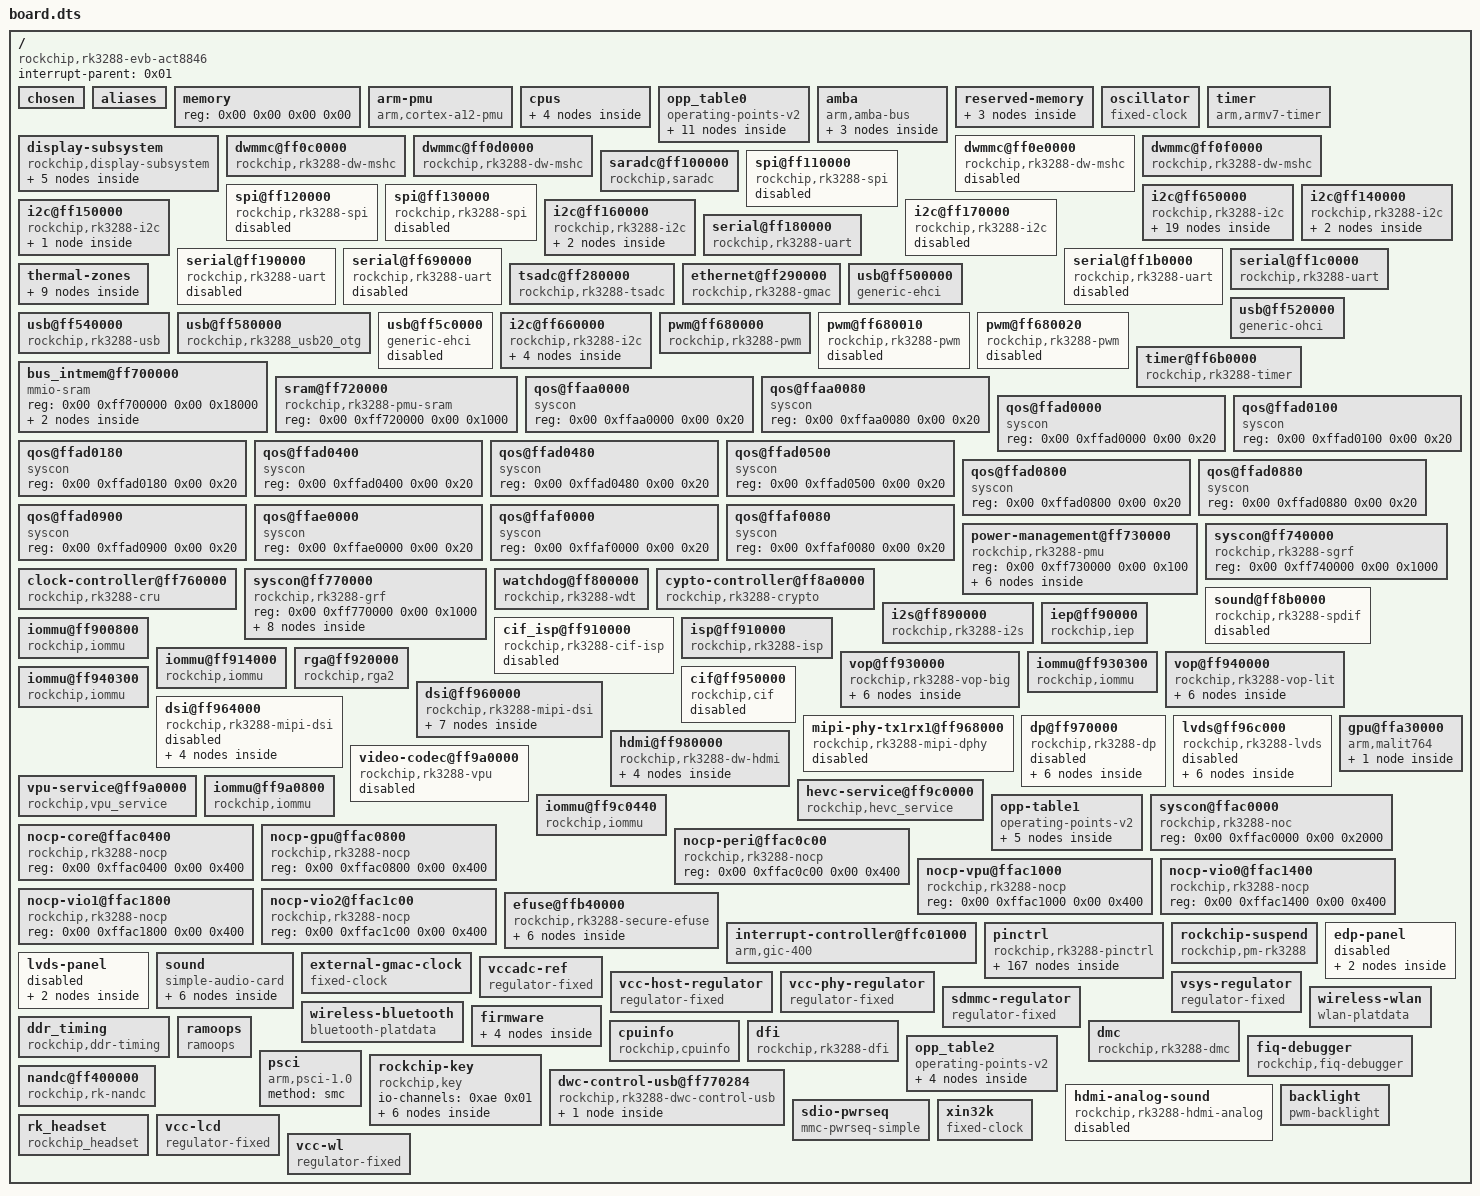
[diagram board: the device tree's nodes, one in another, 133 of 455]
/dts-v1/;

/ {
	#address-cells = <0x02>;
	#size-cells = <0x02>;
	compatible = "rockchip,rk3288-evb-act8846", "rockchip,rk3288";
	interrupt-parent = <0x01>;

	chosen {
		bootargs = "earlycon=uart8250,mmio32,0xff690000 vmalloc=496M";
	};

	aliases {
		ethernet0 = "/ethernet@ff290000";
		i2c0 = "/i2c@ff650000";
		i2c1 = "/i2c@ff140000";
		i2c2 = "/i2c@ff660000";
		i2c3 = "/i2c@ff150000";
		i2c4 = "/i2c@ff160000";
		i2c5 = "/i2c@ff170000";
		mshc0 = "/dwmmc@ff0f0000";
		mshc1 = "/dwmmc@ff0c0000";
		mshc2 = "/dwmmc@ff0d0000";
		mshc3 = "/dwmmc@ff0e0000";
		serial0 = "/serial@ff180000";
		serial1 = "/serial@ff190000";
		serial2 = "/serial@ff690000";
		serial3 = "/serial@ff1b0000";
		serial4 = "/serial@ff1c0000";
		spi0 = "/spi@ff110000";
		spi1 = "/spi@ff120000";
		spi2 = "/spi@ff130000";
		dsi0 = "/dsi@ff960000";
		dsi1 = "/dsi@ff964000";
	};

	memory {
		device_type = "memory";
		reg = <0x00 0x00 0x00 0x00>;
	};

	arm-pmu {
		compatible = "arm,cortex-a12-pmu";
		interrupts = <0x00 0x97 0x04 0x00 0x98 0x04 0x00 0x99 0x04 0x00 0x9a 0x04>;
		interrupt-affinity = <0x02 0x03 0x04 0x05>;
	};

	cpus {
		#address-cells = <0x01>;
		#size-cells = <0x00>;
		enable-method = "rockchip,rk3066-smp";
		rockchip,pmu = <0x06>;

		cpu@500 {
			device_type = "cpu";
			compatible = "arm,cortex-a12";
			reg = <0x500>;
			resets = <0x07 0x00>;
			operating-points-v2 = <0x08>;
			#cooling-cells = <0x02>;
			dynamic-power-coefficient = <0x142>;
			clocks = <0x07 0x06>;
			enable-method = "psci";
			cpu-supply = <0x09>;
			phandle = <0x02>;
		};

		cpu@501 {
			device_type = "cpu";
			compatible = "arm,cortex-a12";
			reg = <0x501>;
			resets = <0x07 0x01>;
			operating-points-v2 = <0x08>;
			enable-method = "psci";
			phandle = <0x03>;
		};

		cpu@502 {
			device_type = "cpu";
			compatible = "arm,cortex-a12";
			reg = <0x502>;
			resets = <0x07 0x02>;
			operating-points-v2 = <0x08>;
			enable-method = "psci";
			phandle = <0x04>;
		};

		cpu@503 {
			device_type = "cpu";
			compatible = "arm,cortex-a12";
			reg = <0x503>;
			resets = <0x07 0x03>;
			operating-points-v2 = <0x08>;
			enable-method = "psci";
			phandle = <0x05>;
		};
	};

	opp_table0 {
		compatible = "operating-points-v2";
		opp-shared;
		clocks = <0x07 0x01>;
		rockchip,avs-scale = <0x11>;
		rockchip,max-volt = <0x149970>;
		nvmem-cells = <0x0a 0x0b 0x0c 0x0d 0x0e>;
		nvmem-cell-names = "leakage", "special", "performance", "process", "performance-w";
		rockchip,bin-scaling-sel = <0x00 0x11 0x01 0x19 0x02 0x1b 0x03 0x1f>;
		rockchip,pvtm-voltage-sel = <0x00 0x37dc 0x00 0x37dd 0x3a98 0x01 0x3a99 0x3e80 0x02 0x3e81 0x1869f 0x03>;
		rockchip,pvtm-freq = <0x639c0>;
		rockchip,pvtm-volt = <0xf4240>;
		rockchip,pvtm-ch = <0x00 0x00>;
		rockchip,pvtm-sample-time = <0x3e8>;
		rockchip,pvtm-number = <0x0a>;
		rockchip,pvtm-error = <0x3e8>;
		rockchip,pvtm-ref-temp = <0x23>;
		rockchip,pvtm-temp-prop = <0xffffffee 0xffffffee>;
		rockchip,pvtm-thermal-zone = "soc-thermal";
		rockchip,avs-enable = <0x01>;
		phandle = <0x08>;

		opp-126000000 {
			opp-hz = <0x00 0x7829b80>;
			opp-microvolt = <0xe7ef0 0xe7ef0 0x149970>;
			opp-microvolt-L0 = <0xe7ef0 0xe7ef0 0x149970>;
			opp-microvolt-L1 = <0xe7ef0 0xe7ef0 0x149970>;
			opp-microvolt-L2 = <0xe7ef0 0xe7ef0 0x149970>;
			opp-microvolt-L3 = <0xe7ef0 0xe7ef0 0x149970>;
			clock-latency-ns = <0x9c40>;
		};

		opp-216000000 {
			opp-hz = <0x00 0xcdfe600>;
			opp-microvolt = <0xe7ef0 0xe7ef0 0x149970>;
			opp-microvolt-L0 = <0xe7ef0 0xe7ef0 0x149970>;
			opp-microvolt-L1 = <0xe7ef0 0xe7ef0 0x149970>;
			opp-microvolt-L2 = <0xe7ef0 0xe7ef0 0x149970>;
			opp-microvolt-L3 = <0xe7ef0 0xe7ef0 0x149970>;
			clock-latency-ns = <0x9c40>;
		};

		opp-408000000 {
			opp-hz = <0x00 0x18519600>;
			opp-microvolt = <0xee098 0xee098 0x149970>;
			opp-microvolt-L0 = <0xee098 0xee098 0x149970>;
			opp-microvolt-L1 = <0xe7ef0 0xe7ef0 0x149970>;
			opp-microvolt-L2 = <0xe7ef0 0xe7ef0 0x149970>;
			opp-microvolt-L3 = <0xe7ef0 0xe7ef0 0x149970>;
			clock-latency-ns = <0x9c40>;
		};

		opp-600000000 {
			opp-hz = <0x00 0x23c34600>;
			opp-microvolt = <0xee098 0xee098 0x149970>;
			opp-microvolt-L0 = <0xee098 0xee098 0x149970>;
			opp-microvolt-L1 = <0xe7ef0 0xe7ef0 0x149970>;
			opp-microvolt-L2 = <0xe7ef0 0xe7ef0 0x149970>;
			opp-microvolt-L3 = <0xe7ef0 0xe7ef0 0x149970>;
			clock-latency-ns = <0x9c40>;
		};

		opp-696000000 {
			opp-hz = <0x00 0x297c1e00>;
			opp-microvolt = <0xee098 0xee098 0x149970>;
			opp-microvolt-L0 = <0xee098 0xee098 0x149970>;
			opp-microvolt-L1 = <0xe7ef0 0xe7ef0 0x149970>;
			opp-microvolt-L2 = <0xe7ef0 0xe7ef0 0x149970>;
			opp-microvolt-L3 = <0xe7ef0 0xe7ef0 0x149970>;
			clock-latency-ns = <0x9c40>;
		};

		opp-816000000 {
			opp-hz = <0x00 0x30a32c00>;
			opp-microvolt = <0x106738 0x106738 0x149970>;
			opp-microvolt-L0 = <0x106738 0x106738 0x149970>;
			opp-microvolt-L1 = <0x100590 0x100590 0x149970>;
			opp-microvolt-L2 = <0xf4240 0xf4240 0x149970>;
			opp-microvolt-L3 = <0xe7ef0 0xe7ef0 0x149970>;
			clock-latency-ns = <0x9c40>;
			opp-suspend;
		};

		opp-1008000000 {
			opp-hz = <0x00 0x3c14dc00>;
			opp-microvolt = <0x118c30 0x118c30 0x149970>;
			opp-microvolt-L0 = <0x118c30 0x118c30 0x149970>;
			opp-microvolt-L1 = <0x10c8e0 0x10c8e0 0x149970>;
			opp-microvolt-L2 = <0x100590 0x100590 0x149970>;
			opp-microvolt-L3 = <0xf4240 0xf4240 0x149970>;
			clock-latency-ns = <0x9c40>;
		};

		opp-1200000000 {
			opp-hz = <0x00 0x47868c00>;
			opp-microvolt = <0x124f80 0x124f80 0x149970>;
			opp-microvolt-L0 = <0x124f80 0x124f80 0x149970>;
			opp-microvolt-L1 = <0x118c30 0x118c30 0x149970>;
			opp-microvolt-L2 = <0x10c8e0 0x10c8e0 0x149970>;
			opp-microvolt-L3 = <0x100590 0x100590 0x149970>;
			clock-latency-ns = <0x9c40>;
		};

		opp-1416000000 {
			opp-hz = <0x00 0x54667200>;
			opp-microvolt = <0x13d620 0x13d620 0x149970>;
			opp-microvolt-L0 = <0x13d620 0x13d620 0x149970>;
			opp-microvolt-L1 = <0x1312d0 0x1312d0 0x149970>;
			opp-microvolt-L2 = <0x124f80 0x124f80 0x149970>;
			opp-microvolt-L3 = <0x118c30 0x118c30 0x149970>;
			clock-latency-ns = <0x9c40>;
		};

		opp-1512000000 {
			opp-hz = <0x00 0x5a1f4a00>;
			opp-microvolt = <0x149970 0x149970 0x149970>;
			opp-microvolt-L0 = <0x149970 0x149970 0x149970>;
			opp-microvolt-L1 = <0x13d620 0x13d620 0x149970>;
			opp-microvolt-L2 = <0x1312d0 0x1312d0 0x149970>;
			opp-microvolt-L3 = <0x124f80 0x124f80 0x149970>;
			clock-latency-ns = <0x9c40>;
		};

		opp-1608000000 {
			opp-hz = <0x00 0x5fd82200>;
			opp-microvolt = <0x149970 0x149970 0x149970>;
			opp-microvolt-L0 = <0x149970 0x149970 0x149970>;
			opp-microvolt-L1 = <0x149970 0x149970 0x149970>;
			opp-microvolt-L2 = <0x13d620 0x13d620 0x149970>;
			opp-microvolt-L3 = <0x1312d0 0x1312d0 0x149970>;
			clock-latency-ns = <0x9c40>;
		};
	};

	amba {
		compatible = "arm,amba-bus";
		#address-cells = <0x02>;
		#size-cells = <0x02>;
		ranges;

		dma-controller@ff250000 {
			compatible = "arm,pl330", "arm,primecell";
			reg = <0x00 0xff250000 0x00 0x4000>;
			interrupts = <0x00 0x02 0x04 0x00 0x03 0x04>;
			#dma-cells = <0x01>;
			arm,pl330-broken-no-flushp;
			peripherals-req-type-burst;
			clocks = <0x07 0xc2>;
			clock-names = "apb_pclk";
			phandle = <0x26>;
		};

		dma-controller@ff600000 {
			compatible = "arm,pl330", "arm,primecell";
			reg = <0x00 0xff600000 0x00 0x4000>;
			interrupts = <0x00 0x00 0x04 0x00 0x01 0x04>;
			#dma-cells = <0x01>;
			arm,pl330-broken-no-flushp;
			peripherals-req-type-burst;
			clocks = <0x07 0xc1>;
			clock-names = "apb_pclk";
			status = "disabled";
		};

		dma-controller@ffb20000 {
			compatible = "arm,pl330", "arm,primecell";
			reg = <0x00 0xff600000 0x00 0x4000>;
			interrupts = <0x00 0x00 0x04 0x00 0x01 0x04>;
			#dma-cells = <0x01>;
			arm,pl330-broken-no-flushp;
			peripherals-req-type-burst;
			clocks = <0x07 0xc1>;
			clock-names = "apb_pclk";
			phandle = <0x69>;
		};
	};

	reserved-memory {
		#address-cells = <0x02>;
		#size-cells = <0x02>;
		ranges;

		dma-unusable@fe000000 {
			reg = <0x00 0xfe000000 0x00 0x1000000>;
		};

		ramoops@00000000 {
			reg = <0x00 0x8000000 0x00 0xf0000>;
			phandle = <0xad>;
		};

		drm-logo@00000000 {
			compatible = "rockchip,drm-logo";
			reg = <0x00 0x00 0x00 0x00>;
			phandle = <0x11>;
		};
	};

	oscillator {
		compatible = "fixed-clock";
		clock-frequency = <0x16e3600>;
		clock-output-names = "xin24m";
		#clock-cells = <0x00>;
		phandle = <0x59>;
	};

	timer {
		compatible = "arm,armv7-timer";
		arm,cpu-registers-not-fw-configured;
		interrupts = <0x01 0x0d 0xf04 0x01 0x0e 0xf04 0x01 0x0b 0xf04 0x01 0x0a 0xf04>;
		clock-frequency = <0x16e3600>;
	};

	display-subsystem {
		compatible = "rockchip,display-subsystem";
		ports = <0x0f 0x10>;
		status = "okay";
		logo-memory-region = <0x11>;

		route {

			route-edp {
				status = "disabled";
				logo,uboot = "logo.bmp";
				logo,kernel = "logo_kernel.bmp";
				logo,mode = "center";
				charge_logo,mode = "center";
				connect = <0x12>;
			};

			route-dsi0 {
				status = "okay";
				logo,uboot = "logo.bmp";
				logo,kernel = "logo_kernel.bmp";
				logo,mode = "center";
				charge_logo,mode = "center";
				connect = <0x13>;
			};

			route-lvds {
				status = "disabled";
				logo,uboot = "logo.bmp";
				logo,kernel = "logo_kernel.bmp";
				logo,mode = "center";
				charge_logo,mode = "center";
				connect = <0x14>;
			};

			route-hdmi {
				status = "disabled";
				logo,uboot = "logo.bmp";
				logo,kernel = "logo_kernel.bmp";
				logo,mode = "center";
				charge_logo,mode = "center";
				connect = <0x15>;
			};
		};
	};

	dwmmc@ff0c0000 {
		compatible = "rockchip,rk3288-dw-mshc";
		clock-freq-min-max = <0x61a80 0x8f0d180>;
		clocks = <0x07 0x1c8 0x07 0x44 0x07 0x72 0x07 0x76>;
		clock-names = "biu", "ciu", "ciu-drive", "ciu-sample";
		fifo-depth = <0x100>;
		interrupts = <0x00 0x20 0x04>;
		reg = <0x00 0xff0c0000 0x00 0x4000>;
		status = "okay";
		supports-sd;
		bus-width = <0x04>;
		cap-mmc-highspeed;
		sd-uhs-sdr12;
		sd-uhs-sdr25;
		sd-uhs-sdr50;
		sd-uhs-sdr104;
		cap-sd-highspeed;
		card-detect-delay = <0xc8>;
		disable-wp;
		num-slots = <0x01>;
		pinctrl-names = "default";
		pinctrl-0 = <0x16 0x17 0x18 0x19>;
		vmmc-supply = <0x1a>;
		vqmmc-supply = <0x1b>;
	};

	dwmmc@ff0d0000 {
		compatible = "rockchip,rk3288-dw-mshc";
		clock-freq-min-max = <0x61a80 0x8f0d180>;
		clocks = <0x07 0x1c9 0x07 0x45 0x07 0x73 0x07 0x77>;
		clock-names = "biu", "ciu", "ciu-drive", "ciu-sample";
		fifo-depth = <0x100>;
		interrupts = <0x00 0x21 0x04>;
		reg = <0x00 0xff0d0000 0x00 0x4000>;
		status = "okay";
		max-frequency = <0x8f0d180>;
		bus-width = <0x04>;
		cap-sd-highspeed;
		disable-wp;
		keep-power-in-suspend;
		mmc-pwrseq = <0x1c>;
		non-removable;
		num-slots = <0x01>;
		pinctrl-names = "default";
		pinctrl-0 = <0x1d 0x1e 0x1f 0x20>;
		sd-uhs-sdr104;
		supports-sdio;
	};

	dwmmc@ff0e0000 {
		compatible = "rockchip,rk3288-dw-mshc";
		clock-freq-min-max = <0x61a80 0x8f0d180>;
		clocks = <0x07 0x1ca 0x07 0x46 0x07 0x74 0x07 0x78>;
		clock-names = "biu", "ciu", "ciu-drive", "ciu-sample";
		fifo-depth = <0x100>;
		interrupts = <0x00 0x22 0x04>;
		reg = <0x00 0xff0e0000 0x00 0x4000>;
		status = "disabled";
	};

	dwmmc@ff0f0000 {
		compatible = "rockchip,rk3288-dw-mshc";
		clock-freq-min-max = <0x61a80 0x8f0d180>;
		clocks = <0x07 0x1cb 0x07 0x47 0x07 0x75 0x07 0x79>;
		clock-names = "biu", "ciu", "ciu-drive", "ciu-sample";
		fifo-depth = <0x100>;
		interrupts = <0x00 0x23 0x04>;
		reg = <0x00 0xff0f0000 0x00 0x4000>;
		status = "okay";
		supports-emmc;
		bus-width = <0x08>;
		cap-mmc-highspeed;
		disable-wp;
		non-removable;
		num-slots = <0x01>;
		pinctrl-names = "default";
		pinctrl-0 = <0x21 0x22 0x23 0x24>;
		max-frequency = <0x5f5e100>;
		mmc-hs200-1_8v;
		mmc-ddr-1_8v;
	};

	saradc@ff100000 {
		compatible = "rockchip,saradc";
		reg = <0x00 0xff100000 0x00 0x100>;
		interrupts = <0x00 0x24 0x04>;
		#io-channel-cells = <0x01>;
		clocks = <0x07 0x49 0x07 0x15b>;
		clock-names = "saradc", "apb_pclk";
		resets = <0x07 0x57>;
		reset-names = "saradc-apb";
		status = "okay";
		vref-supply = <0x25>;
		phandle = <0xae>;
	};

	spi@ff110000 {
		compatible = "rockchip,rk3288-spi", "rockchip,rk3066-spi";
		clocks = <0x07 0x41 0x07 0x152>;
		clock-names = "spiclk", "apb_pclk";
		dmas = <0x26 0x0b 0x26 0x0c>;
		dma-names = "tx", "rx";
		interrupts = <0x00 0x2c 0x04>;
		pinctrl-names = "default";
		pinctrl-0 = <0x27 0x28 0x29 0x2a>;
		reg = <0x00 0xff110000 0x00 0x1000>;
		#address-cells = <0x01>;
		#size-cells = <0x00>;
		status = "disabled";
	};

	spi@ff120000 {
		compatible = "rockchip,rk3288-spi", "rockchip,rk3066-spi";
		clocks = <0x07 0x42 0x07 0x153>;
		clock-names = "spiclk", "apb_pclk";
		dmas = <0x26 0x0d 0x26 0x0e>;
		dma-names = "tx", "rx";
		interrupts = <0x00 0x2d 0x04>;
		pinctrl-names = "default";
		#pinctrl-0 = <0x2b 0x2c 0x2d 0x2e>;
		reg = <0x00 0xff120000 0x00 0x1000>;
		#address-cells = <0x01>;
		#size-cells = <0x00>;
		status = "disabled";
	};

	spi@ff130000 {
		compatible = "rockchip,rk3288-spi", "rockchip,rk3066-spi";
		clocks = <0x07 0x43 0x07 0x154>;
		clock-names = "spiclk", "apb_pclk";
		dmas = <0x26 0x0f 0x26 0x10>;
		dma-names = "tx", "rx";
		interrupts = <0x00 0x2e 0x04>;
		pinctrl-names = "default";
		pinctrl-0 = <0x2f 0x30 0x31 0x32>;
		reg = <0x00 0xff130000 0x00 0x1000>;
		#address-cells = <0x01>;
		#size-cells = <0x00>;
		status = "disabled";
	};

	i2c@ff650000 {
		compatible = "rockchip,rk3288-i2c";
		reg = <0x00 0xff650000 0x00 0x1000>;
		interrupts = <0x00 0x3c 0x04>;
		#address-cells = <0x01>;
		#size-cells = <0x00>;
		clock-names = "i2c";
		clocks = <0x07 0x14c>;
		pinctrl-names = "default";
		pinctrl-0 = <0x33>;
		status = "okay";
		clock-frequency = <0x61a80>;

		syr827@40 {
			compatible = "silergy,syr827";
			fcs,suspend-voltage-selector = <0x01>;
			reg = <0x40>;
			regulator-name = "vdd_cpu";
			regulator-min-microvolt = <0xcf850>;
			regulator-max-microvolt = <0x149970>;
			regulator-always-on;
			regulator-boot-on;
			regulator-enable-ramp-delay = <0x12c>;
			regulator-ramp-delay = <0x1f40>;
			vin-supply = <0x34>;
			phandle = <0x09>;

			regulator-state-mem {
				regulator-off-in-suspend;
			};
		};

		syr828@41 {
			compatible = "silergy,syr828";
			fcs,suspend-voltage-selector = <0x01>;
			reg = <0x41>;
			regulator-name = "vdd_gpu";
			regulator-min-microvolt = <0xcf850>;
			regulator-max-microvolt = <0x149970>;
			regulator-always-on;
			regulator-ramp-delay = <0x1770>;
			vin-supply = <0x34>;
			phandle = <0x95>;

			regulator-state-mem {
				regulator-off-in-suspend;
			};
		};

		hym8563@51 {
			compatible = "rtc,hym8563";
			reg = <0x51>;
			phandle = <0xb3>;
		};

		act8846@5a {
			compatible = "active-semi,act8846";
			reg = <0x5a>;
			status = "okay";
			vp1-supply = <0x34>;
			vp2-supply = <0x34>;
			vp3-supply = <0x34>;
			vp4-supply = <0x34>;
			inl1-supply = <0x35>;
			inl2-supply = <0x34>;
			inl3-supply = <0x36>;

			regulators {

				REG1 {
					regulator-name = "VCC_DDR";
					regulator-min-microvolt = <0x124f80>;
					regulator-max-microvolt = <0x124f80>;
					regulator-always-on;
				};

				REG2 {
					regulator-name = "VCC_IO";
					regulator-min-microvolt = <0x325aa0>;
					regulator-max-microvolt = <0x325aa0>;
					regulator-always-on;
					phandle = <0x35>;
				};

				REG3 {
					regulator-name = "VDD_LOG";
					regulator-min-microvolt = <0x118c30>;
					regulator-max-microvolt = <0x118c30>;
					regulator-always-on;
					phandle = <0xac>;
				};

				REG4 {
					regulator-name = "VCC_20";
					regulator-min-microvolt = <0x1e8480>;
					regulator-max-microvolt = <0x1e8480>;
					regulator-always-on;
					phandle = <0x36>;
				};

				REG5 {
					regulator-name = "VCCIO_SD";
					regulator-min-microvolt = <0x1b7740>;
					regulator-max-microvolt = <0x325aa0>;
					regulator-always-on;
					phandle = <0x1b>;
				};

				REG6 {
					regulator-name = "VDD10_LCD";
					regulator-min-microvolt = <0xf4240>;
					regulator-max-microvolt = <0xf4240>;
					regulator-always-on;
				};

				REG7 {
					regulator-name = "VCCA_CODEC";
					regulator-min-microvolt = <0x325aa0>;
					regulator-max-microvolt = <0x325aa0>;
					regulator-always-on;
				};

				REG8 {
					regulator-name = "VCCA_TP";
					regulator-min-microvolt = <0x325aa0>;
					regulator-max-microvolt = <0x325aa0>;
					regulator-always-on;
				};

				REG9 {
					regulator-name = "VCCIO_PMU";
					regulator-min-microvolt = <0x325aa0>;
					regulator-max-microvolt = <0x325aa0>;
					regulator-always-on;
				};

				REG10 {
					regulator-name = "VDD_10";
					regulator-min-microvolt = <0xf4240>;
					regulator-max-microvolt = <0xf4240>;
					regulator-always-on;
				};

				REG11 {
					regulator-name = "VCC_18";
					regulator-min-microvolt = <0x1b7740>;
					regulator-max-microvolt = <0x1b7740>;
					regulator-always-on;
					phandle = <0x68>;
				};

				REG12 {
					regulator-name = "VCC18_LCD";
					regulator-min-microvolt = <0x1b7740>;
					regulator-max-microvolt = <0x1b7740>;
					regulator-always-on;
				};
			};
		};
	};

	i2c@ff140000 {
		compatible = "rockchip,rk3288-i2c";
		reg = <0x00 0xff140000 0x00 0x1000>;
		interrupts = <0x00 0x3e 0x04>;
		#address-cells = <0x01>;
		#size-cells = <0x00>;
		clock-names = "i2c";
		clocks = <0x07 0x14d>;
		pinctrl-names = "default";
		pinctrl-0 = <0x37>;
		status = "okay";
		clock-frequency = <0x61a80>;

		sensor@18 {
			status = "okay";
			compatible = "bma2xx_acc";
			reg = <0x18>;
			type = <0x02>;
			irq-gpio = <0x38 0x0a 0x08>;
			irq_enable = <0x00>;
			poll_delay_ms = <0x1e>;
			layout = <0x05>;
		};

		sensor@27 {
			compatible = "gs_mir3da";
			reg = <0x27>;
			type = <0x02>;
			irq_enable = <0x00>;
			poll_delay_ms = <0x1e>;
			layout = <0x06>;
		};
	};

	i2c@ff150000 {
		compatible = "rockchip,rk3288-i2c";
		reg = <0x00 0xff150000 0x00 0x1000>;
		interrupts = <0x00 0x3f 0x04>;
		#address-cells = <0x01>;
		#size-cells = <0x00>;
		clock-names = "i2c";
		clocks = <0x07 0x14f>;
		pinctrl-names = "default";
		pinctrl-0 = <0x39>;
		status = "okay";

		camera-module@10 {
			status = "disabled";
			compatible = "omnivision,ov8858-v4l2-i2c-subdev";
			reg = <0x10>;
			device_type = "v4l2-i2c-subdev";
			clocks = <0x07 0x7f>;
			clock-names = "clk_cif_out";
			pinctrl-names = "rockchip,camera_default", "rockchip,camera_sleep";
			pinctrl-0 = <0x3a>;
			pinctrl-1 = <0x3b>;
			rockchip,pd-gpio = <0x3c 0x0f 0x01>;
			rockchip,pwr-gpio = <0x3d 0x11 0x00>;
			rockchip,camera-module-mclk-name = "clk_cif_out";
			rockchip,camera-module-dovdd = "1.8v";
			rockchip,camera-module-facing = "back";
			rockchip,camera-module-name = "cmk-cb0695-fv1";
			rockchip,camera-module-len-name = "lg9569a2";
			rockchip,camera-module-fov-h = "66.0";
			rockchip,camera-module-fov-v = "50.1";
			rockchip,camera-module-orientation = <0x00>;
			rockchip,camera-module-iq-flip = <0x00>;
			rockchip,camera-module-iq-mirror = <0x00>;
			rockchip,camera-module-flip = <0x00>;
			rockchip,camera-module-mirror = <0x00>;
			rockchip,camera-module-defrect0 = <0xcc0 0x990 0x00 0x00 0xcc0 0x990>;
			rockchip,camera-module-flash-support = <0x00>;
			rockchip,camera-module-mipi-dphy-index = <0x00>;
			phandle = <0x6f>;
		};
	};

	i2c@ff160000 {
		compatible = "rockchip,rk3288-i2c";
		reg = <0x00 0xff160000 0x00 0x1000>;
		interrupts = <0x00 0x40 0x04>;
		#address-cells = <0x01>;
		#size-cells = <0x00>;
		clock-names = "i2c";
		clocks = <0x07 0x150>;
		pinctrl-names = "default";
		pinctrl-0 = <0x3e>;
		status = "okay";
		clock-frequency = <0x61a80>;

		gsl3673@40 {
			compatible = "GSL,GSL3673";
			reg = <0x40>;
			screen_max_x = <0x600>;
			screen_max_y = <0x800>;
			irq_gpio_number = <0x3f 0x06 0x08>;
			rst_gpio_number = <0x3f 0x05 0x00>;
			status = "okay";
		};

		ts@5d {
			compatible = "goodix,gt9xx";
			reg = <0x5d>;
			touch-gpio = <0x3f 0x06 0x08>;
			reset-gpio = <0x3f 0x05 0x01>;
			max-x = <0x500>;
			max-y = <0x320>;
			tp-size = <0x59>;
		};
	};

	i2c@ff170000 {
		compatible = "rockchip,rk3288-i2c";
		reg = <0x00 0xff170000 0x00 0x1000>;
		interrupts = <0x00 0x41 0x04>;
		#address-cells = <0x01>;
		#size-cells = <0x00>;
		clock-names = "i2c";
		clocks = <0x07 0x151>;
		pinctrl-names = "default";
		pinctrl-0 = <0x40>;
		status = "disabled";
	};

	serial@ff180000 {
		compatible = "rockchip,rk3288-uart", "snps,dw-apb-uart";
		reg = <0x00 0xff180000 0x00 0x100>;
		interrupts = <0x00 0x37 0x04>;
		reg-shift = <0x02>;
		reg-io-width = <0x04>;
		clocks = <0x07 0x4d 0x07 0x155>;
		clock-names = "baudclk", "apb_pclk";
		pinctrl-names = "default";
		pinctrl-0 = <0x41 0x42>;
		status = "okay";
	};

	serial@ff190000 {
		compatible = "rockchip,rk3288-uart", "snps,dw-apb-uart";
		reg = <0x00 0xff190000 0x00 0x100>;
		interrupts = <0x00 0x38 0x04>;
		reg-shift = <0x02>;
		reg-io-width = <0x04>;
		clocks = <0x07 0x4e 0x07 0x156>;
		clock-names = "baudclk", "apb_pclk";
		pinctrl-names = "default";
		pinctrl-0 = <0x43>;
		status = "disabled";
	};

	serial@ff690000 {
		compatible = "rockchip,rk3288-uart", "snps,dw-apb-uart";
		reg = <0x00 0xff690000 0x00 0x100>;
		interrupts = <0x00 0x39 0x04>;
		reg-shift = <0x02>;
		reg-io-width = <0x04>;
		clocks = <0x07 0x4f 0x07 0x157>;
		clock-names = "baudclk", "apb_pclk";
		pinctrl-names = "default";
		status = "disabled";
	};

	serial@ff1b0000 {
		compatible = "rockchip,rk3288-uart", "snps,dw-apb-uart";
		reg = <0x00 0xff1b0000 0x00 0x100>;
		interrupts = <0x00 0x3a 0x04>;
		reg-shift = <0x02>;
		reg-io-width = <0x04>;
		clocks = <0x07 0x50 0x07 0x158>;
		clock-names = "baudclk", "apb_pclk";
		pinctrl-names = "default";
		pinctrl-0 = <0x44>;
		status = "disabled";
	};

	serial@ff1c0000 {
		compatible = "rockchip,rk3288-uart", "snps,dw-apb-uart";
		reg = <0x00 0xff1c0000 0x00 0x100>;
		interrupts = <0x00 0x3b 0x04>;
		reg-shift = <0x02>;
		reg-io-width = <0x04>;
		clocks = <0x07 0x51 0x07 0x159>;
		clock-names = "baudclk", "apb_pclk";
		pinctrl-names = "default";
		pinctrl-0 = <0x45>;
		status = "okay";
	};

	thermal-zones {

		soc-thermal {
			polling-delay-passive = <0xc8>;
			polling-delay = <0x3e8>;
			sustainable-power = <0x4b0>;
			thermal-sensors = <0x46 0x01>;

			trips {

				trip-point@0 {
					temperature = <0x124f8>;
					hysteresis = <0x7d0>;
					type = "passive";
				};

				trip-point@1 {
					temperature = <0x14c08>;
					hysteresis = <0x7d0>;
					type = "passive";
					phandle = <0x47>;
				};

				soc-crit {
					temperature = <0x1c138>;
					hysteresis = <0x7d0>;
					type = "critical";
				};
			};

			cooling-maps {

				map0 {
					trip = <0x47>;
					cooling-device = <0x02 0xffffffff 0xffffffff>;
					contribution = <0x400>;
				};

				map1 {
					trip = <0x47>;
					cooling-device = <0x48 0xffffffff 0xffffffff>;
					contribution = <0x400>;
				};
			};
		};

		gpu-thermal {
			polling-delay-passive = <0xc8>;
			polling-delay = <0x3e8>;
			thermal-sensors = <0x46 0x02>;
		};
	};

	tsadc@ff280000 {
		compatible = "rockchip,rk3288-tsadc";
		reg = <0x00 0xff280000 0x00 0x100>;
		interrupts = <0x00 0x25 0x04>;
		clocks = <0x07 0x48 0x07 0x15a>;
		clock-names = "tsadc", "apb_pclk";
		assigned-clocks = <0x07 0x48>;
		assigned-clock-rates = <0x1388>;
		resets = <0x07 0x9f>;
		reset-names = "tsadc-apb";
		pinctrl-names = "init", "default", "sleep";
		pinctrl-0 = <0x49>;
		pinctrl-1 = <0x49>;
		pinctrl-2 = <0x49>;
		#thermal-sensor-cells = <0x01>;
		rockchip,hw-tshut-temp = <0x1d4c0>;
		rockchip,hw-tshut-mode = <0x00>;
		status = "okay";
		rockchip,hw-tshut-polarity = <0x00>;
		phandle = <0x46>;
	};

	ethernet@ff290000 {
		compatible = "rockchip,rk3288-gmac";
		reg = <0x00 0xff290000 0x00 0x10000>;
		interrupts = <0x00 0x1b 0x04 0x00 0x1c 0x04>;
		interrupt-names = "macirq", "eth_wake_irq";
		rockchip,grf = <0x4a>;
		clocks = <0x07 0x97 0x07 0x66 0x07 0x67 0x07 0x63 0x07 0x98 0x07 0xc4 0x07 0x15d>;
		clock-names = "stmmaceth", "mac_clk_rx", "mac_clk_tx", "clk_mac_ref", "clk_mac_refout", "aclk_mac", "pclk_mac";
		resets = <0x07 0x42>;
		reset-names = "stmmaceth";
		status = "okay";
		phy-supply = <0x4b>;
		phy-mode = "rgmii";
		clock_in_out = "input";
		snps,reset-gpio = <0x4c 0x08 0x00>;
		snps,reset-active-low;
		snps,reset-delays-us = <0x00 0x2710 0xc350>;
		assigned-clocks = <0x07 0x97>;
		assigned-clock-parents = <0x4d>;
		pinctrl-names = "default";
		pinctrl-0 = <0x4e>;
		tx_delay = <0x30>;
		rx_delay = <0x10>;
		max-speed = <0x64>;
	};

	usb@ff500000 {
		compatible = "generic-ehci";
		reg = <0x00 0xff500000 0x00 0x20000>;
		interrupts = <0x00 0x18 0x04>;
		clocks = <0x07 0x1c2 0x4f>;
		clock-names = "usbhost", "utmi";
		phys = <0x4f>;
		phy-names = "usb";
		status = "okay";
		rockchip-relinquish-port;
	};

	usb@ff520000 {
		compatible = "generic-ohci";
		reg = <0x00 0xff520000 0x00 0x20000>;
		interrupts = <0x00 0x29 0x04>;
		clocks = <0x07 0x1c2 0x4f>;
		clock-names = "usbhost", "utmi";
		phys = <0x4f>;
		phy-names = "usb";
		status = "okay";
	};

	usb@ff540000 {
		compatible = "rockchip,rk3288-usb", "rockchip,rk3066-usb", "snps,dwc2";
		reg = <0x00 0xff540000 0x00 0x40000>;
		interrupts = <0x00 0x19 0x04>;
		clocks = <0x07 0x1c3>;
		clock-names = "otg";
		dr_mode = "host";
		phys = <0x50>;
		phy-names = "usb2-phy";
		status = "okay";
	};

	usb@ff580000 {
		compatible = "rockchip,rk3288_usb20_otg";
		reg = <0x00 0xff580000 0x00 0x40000>;
		interrupts = <0x00 0x17 0x04>;
		clocks = <0x51 0x07 0x1c1>;
		clock-names = "clk_usbphy0", "hclk_usb0";
		dr_mode = "otg";
		g-np-tx-fifo-size = <0x10>;
		g-rx-fifo-size = <0x118>;
		g-tx-fifo-size = <0x100 0x80 0x80 0x40 0x20 0x10>;
		g-use-dma;
		phys = <0x51>;
		phy-names = "usb2-phy";
		status = "okay";
		resets = <0x07 0x84 0x07 0x85 0x07 0x86>;
		reset-names = "otg_ahb", "otg_phy", "otg_controller";
		rockchip,usb-mode = <0x00>;
	};

	usb@ff5c0000 {
		compatible = "generic-ehci";
		reg = <0x00 0xff5c0000 0x00 0x100>;
		interrupts = <0x00 0x1a 0x04>;
		clocks = <0x07 0x1c4>;
		clock-names = "usbhost";
		status = "disabled";
	};

	i2c@ff660000 {
		compatible = "rockchip,rk3288-i2c";
		reg = <0x00 0xff660000 0x00 0x1000>;
		interrupts = <0x00 0x3d 0x04>;
		#address-cells = <0x01>;
		#size-cells = <0x00>;
		clock-names = "i2c";
		clocks = <0x07 0x14e>;
		pinctrl-names = "default";
		pinctrl-0 = <0x52>;
		status = "okay";
		clock-frequency = <0x61a80>;

		rt5640@1c {
			status = "disabled";
			#sound-dai-cells = <0x00>;
			compatible = "realtek,rt5640";
			reg = <0x1c>;
			clocks = <0x07 0x71>;
			clock-names = "mclk";
			interrupt-parent = <0x53>;
			interrupts = <0x07 0x02>;
			pinctrl-names = "default";
			pinctrl-0 = <0x54>;
			phandle = <0xb0>;
		};

		rt5631@1a {
			status = "disabled";
			compatible = "rt5631";
			reg = <0x1a>;
		};

		es8316@10 {
			status = "okay";
			#sound-dai-cells = <0x00>;
			compatible = "everest,es8316";
			reg = <0x10>;
			clocks = <0x07 0x71>;
			clock-names = "mclk";
			spk-con-gpio = <0x3f 0x08 0x00>;
			spk_volume = <0x99>;
			pinctrl-names = "default";
			pinctrl-0 = <0x54>;
			phandle = <0xa0>;
		};

		nfc-bcm2079x@76 {
			compatible = "nfc-bcm2079x.ap6441";
			reg = <0x76>;
			pw_gpio = <0x3f 0x15 0x00>;
			en_gpio = <0x3f 0x0e 0x00>;
			wake_gpio = <0x3f 0x0f 0x00>;
			irq_gpio = <0x3d 0x01 0x01>;
			status = "okay";
		};
	};

	pwm@ff680000 {
		compatible = "rockchip,rk3288-pwm";
		reg = <0x00 0xff680000 0x00 0x10>;
		#pwm-cells = <0x03>;
		pinctrl-names = "active";
		pinctrl-0 = <0x55>;
		clocks = <0x07 0x15e>;
		clock-names = "pwm";
		status = "okay";
		phandle = <0xb2>;
	};

	pwm@ff680010 {
		compatible = "rockchip,rk3288-pwm";
		reg = <0x00 0xff680010 0x00 0x10>;
		#pwm-cells = <0x03>;
		pinctrl-names = "active";
		pinctrl-0 = <0x56>;
		clocks = <0x07 0x15e>;
		clock-names = "pwm";
		status = "disabled";
	};

	pwm@ff680020 {
		compatible = "rockchip,rk3288-pwm";
		reg = <0x00 0xff680020 0x00 0x10>;
		#pwm-cells = <0x03>;
		pinctrl-names = "active";
		pinctrl-0 = <0x57>;
		clocks = <0x07 0x15e>;
		clock-names = "pwm";
		status = "disabled";
	};


	timer@ff6b0000 {
		compatible = "rockchip,rk3288-timer";
		reg = <0x00 0xff6b0000 0x00 0x20>;
		interrupts = <0x00 0x42 0x04>;
		clocks = <0x59 0x07 0x161>;
		clock-names = "timer", "pclk";
	};

	bus_intmem@ff700000 {
		compatible = "mmio-sram";
		reg = <0x00 0xff700000 0x00 0x18000>;
		#address-cells = <0x01>;
		#size-cells = <0x01>;
		ranges = <0x00 0x00 0xff700000 0x18000>;

		smp-sram@0 {
			compatible = "rockchip,rk3066-smp-sram";
			reg = <0x00 0x10>;
		};

		ddr-sram@1000 {
			compatible = "rockchip,rk3288-ddr-sram";
			reg = <0x1000 0x4000>;
		};
	};

	sram@ff720000 {
		compatible = "rockchip,rk3288-pmu-sram", "mmio-sram";
		reg = <0x00 0xff720000 0x00 0x1000>;
	};

	qos@ffaa0000 {
		compatible = "syscon";
		reg = <0x00 0xffaa0000 0x00 0x20>;
		phandle = <0x66>;
	};

	qos@ffaa0080 {
		compatible = "syscon";
		reg = <0x00 0xffaa0080 0x00 0x20>;
		phandle = <0x67>;
	};

	qos@ffad0000 {
		compatible = "syscon";
		reg = <0x00 0xffad0000 0x00 0x20>;
		phandle = <0x5b>;
	};

	qos@ffad0100 {
		compatible = "syscon";
		reg = <0x00 0xffad0100 0x00 0x20>;
		phandle = <0x5c>;
	};

	qos@ffad0180 {
		compatible = "syscon";
		reg = <0x00 0xffad0180 0x00 0x20>;
		phandle = <0x5d>;
	};

	qos@ffad0400 {
		compatible = "syscon";
		reg = <0x00 0xffad0400 0x00 0x20>;
		phandle = <0x5e>;
	};

	qos@ffad0480 {
		compatible = "syscon";
		reg = <0x00 0xffad0480 0x00 0x20>;
		phandle = <0x5f>;
	};

	qos@ffad0500 {
		compatible = "syscon";
		reg = <0x00 0xffad0500 0x00 0x20>;
		phandle = <0x5a>;
	};

	qos@ffad0800 {
		compatible = "syscon";
		reg = <0x00 0xffad0800 0x00 0x20>;
		phandle = <0x60>;
	};

	qos@ffad0880 {
		compatible = "syscon";
		reg = <0x00 0xffad0880 0x00 0x20>;
		phandle = <0x61>;
	};

	qos@ffad0900 {
		compatible = "syscon";
		reg = <0x00 0xffad0900 0x00 0x20>;
		phandle = <0x62>;
	};

	qos@ffae0000 {
		compatible = "syscon";
		reg = <0x00 0xffae0000 0x00 0x20>;
		phandle = <0x65>;
	};

	qos@ffaf0000 {
		compatible = "syscon";
		reg = <0x00 0xffaf0000 0x00 0x20>;
		phandle = <0x63>;
	};

	qos@ffaf0080 {
		compatible = "syscon";
		reg = <0x00 0xffaf0080 0x00 0x20>;
		phandle = <0x64>;
	};

	power-management@ff730000 {
		compatible = "rockchip,rk3288-pmu", "syscon", "simple-mfd";
		reg = <0x00 0xff730000 0x00 0x100>;
		phandle = <0x06>;

		power-controller {
			compatible = "rockchip,rk3288-power-controller";
			#power-domain-cells = <0x01>;
			#address-cells = <0x01>;
			#size-cells = <0x00>;
			phandle = <0x6d>;

			pd_vio@9 {
				reg = <0x09>;
				clocks = <0x07 0xca 0x07 0xcd 0x07 0xc8 0x07 0xcc 0x07 0xc5 0x07 0xc6 0x07 0xbe 0x07 0xbf 0x07 0x1d4 0x07 0x1d5 0x07 0x1d6 0x07 0x1d9 0x07 0x1d1 0x07 0x1d2 0x07 0x163 0x07 0x168 0x07 0x167 0x07 0x166 0x07 0x164 0x07 0x165 0x07 0x68 0x07 0x69 0x07 0x6c 0x07 0x6b 0x07 0x6a>;
				pm_qos = <0x5a 0x5b 0x5c 0x5d 0x5e 0x5f 0x60 0x61 0x62>;
			};

			pd_hevc@11 {
				reg = <0x0b>;
				clocks = <0x07 0xcf 0x07 0x6f 0x07 0x70>;
				pm_qos = <0x63 0x64>;
			};

			pd_video@12 {
				reg = <0x0c>;
				clocks = <0x07 0xd0 0x07 0x1dc>;
				pm_qos = <0x65>;
			};

			pd_gpu@13 {
				reg = <0x0d>;
				clocks = <0x07 0xc0>;
				pm_qos = <0x66 0x67>;
			};
		};

		reboot-mode {
			compatible = "syscon-reboot-mode";
			offset = <0x94>;
			mode-normal = <0x5242c300>;
			mode-recovery = <0x5242c303>;
			mode-bootloader = <0x5242c309>;
			mode-loader = <0x5242c301>;
			mode-ums = <0x5242c30c>;
		};
	};

	syscon@ff740000 {
		compatible = "rockchip,rk3288-sgrf", "syscon";
		reg = <0x00 0xff740000 0x00 0x1000>;
	};

	clock-controller@ff760000 {
		compatible = "rockchip,rk3288-cru";
		reg = <0x00 0xff760000 0x00 0x1000>;
		rockchip,grf = <0x4a>;
		#clock-cells = <0x01>;
		#reset-cells = <0x01>;
		assigned-clocks = <0x07 0x04 0x07 0x05 0x07 0xd1 0x07 0x1dd 0x07 0x16a 0x07 0xd2 0x07 0x1de 0x07 0x16b>;
		assigned-clock-rates = <0x2367b880 0x1dcd6500 0x11e1a300 0x8f0d180 0x47868c0 0x11e1a300 0x8f0d180 0x47868c0>;
		phandle = <0x07>;
	};

	syscon@ff770000 {
		compatible = "rockchip,rk3288-grf", "syscon", "simple-mfd";
		reg = <0x00 0xff770000 0x00 0x1000>;
		phandle = <0x4a>;

		edp-phy {
			compatible = "rockchip,rk3288-dp-phy";
			clocks = <0x07 0x68>;
			clock-names = "24m";
			#phy-cells = <0x00>;
			status = "disabled";
			phandle = <0x8a>;
		};

		mipi-phy-rx0 {
			compatible = "rockchip,rk3288-mipi-dphy";
			clocks = <0x07 0x7e 0x07 0x166>;
			clock-names = "dphy-ref", "pclk";
			status = "disabled";
		};

		io-domains {
			compatible = "rockchip,rk3288-io-voltage-domain";
			status = "okay";
			sdcard-supply = <0x1b>;
			wifi-supply = <0x68>;
		};

		usbphy {
			compatible = "rockchip,rk3288-usb-phy";
			#address-cells = <0x01>;
			#size-cells = <0x00>;
			status = "okay";

			usb-phy@320 {
				#phy-cells = <0x00>;
				reg = <0x320>;
				clocks = <0x07 0x5d>;
				clock-names = "phyclk";
				#clock-cells = <0x00>;
				resets = <0x07 0x85>;
				reset-names = "phy-reset";
				phandle = <0x51>;
			};

			usb-phy@334 {
				#phy-cells = <0x00>;
				reg = <0x334>;
				clocks = <0x07 0x5e>;
				clock-names = "phyclk";
				#clock-cells = <0x00>;
				phandle = <0x4f>;
			};

			usb-phy@348 {
				#phy-cells = <0x00>;
				reg = <0x348>;
				clocks = <0x07 0x5f>;
				clock-names = "phyclk";
				#clock-cells = <0x00>;
				resets = <0x07 0x8b>;
				reset-names = "phy-reset";
				phandle = <0x50>;
			};
		};

		pvtm {
			compatible = "rockchip,rk3288-pvtm";
			clocks = <0x07 0x7b 0x07 0x7c>;
			clock-names = "core", "gpu";
			resets = <0x07 0x7c 0x07 0x7d>;
			reset-names = "core", "gpu";
			status = "okay";
		};
	};

	watchdog@ff800000 {
		compatible = "rockchip,rk3288-wdt", "snps,dw-wdt";
		reg = <0x00 0xff800000 0x00 0x100>;
		clocks = <0x07 0x170>;
		interrupts = <0x00 0x4f 0x04>;
		status = "okay";
	};

	cypto-controller@ff8a0000 {
		compatible = "rockchip,rk3288-crypto";
		reg = <0x00 0xff8a0000 0x00 0x4000>;
		interrupts = <0x00 0x30 0x04>;
		clocks = <0x07 0xc7 0x07 0x1cd 0x07 0x7d 0x07 0xc1>;
		clock-names = "aclk", "hclk", "sclk", "apb_pclk";
		resets = <0x07 0xae>;
		reset-names = "crypto-rst";
		status = "okay";
	};

	sound@ff8b0000 {
		compatible = "rockchip,rk3288-spdif", "rockchip,rk3066-spdif";
		reg = <0x00 0xff8b0000 0x00 0x10000>;
		#sound-dai-cells = <0x00>;
		clock-names = "hclk", "mclk";
		clocks = <0x07 0x1d0 0x07 0x54>;
		dmas = <0x69 0x03>;
		dma-names = "tx";
		interrupts = <0x00 0x36 0x04>;
		pinctrl-names = "default";
		pinctrl-0 = <0x6a>;
		rockchip,grf = <0x4a>;
		status = "disabled";
	};

	i2s@ff890000 {
		compatible = "rockchip,rk3288-i2s", "rockchip,rk3066-i2s";
		reg = <0x00 0xff890000 0x00 0x10000>;
		interrupts = <0x00 0x35 0x04>;
		#address-cells = <0x01>;
		#size-cells = <0x00>;
		dmas = <0x69 0x00 0x69 0x01>;
		dma-names = "tx", "rx";
		clock-names = "i2s_hclk", "i2s_clk";
		clocks = <0x07 0x1ce 0x07 0x52>;
		assigned-clocks = <0x07 0x81>;
		assigned-clock-parents = <0x07 0x04>;
		pinctrl-names = "default";
		pinctrl-0 = <0x6b>;
		rockchip,playback-channels = <0x08>;
		rockchip,capture-channels = <0x02>;
		status = "okay";
		#sound-dai-cells = <0x00>;
		phandle = <0x9f>;
	};

	iep@ff90000 {
		compatible = "rockchip,iep";
		iommu_enabled = <0x01>;
		iommus = <0x6c>;
		reg = <0x00 0xff900000 0x00 0x800>;
		interrupts = <0x00 0x11 0x04>;
		clocks = <0x07 0xca 0x07 0x1d4>;
		clock-names = "aclk_iep", "hclk_iep";
		power-domains = <0x6d 0x09>;
		allocator = <0x01>;
		version = <0x01>;
		status = "okay";
	};

	iommu@ff900800 {
		compatible = "rockchip,iommu";
		reg = <0x00 0xff900800 0x00 0x40>;
		interrupts = <0x00 0x11 0x04>;
		interrupt-names = "iep_mmu";
		#iommu-cells = <0x00>;
		status = "okay";
		phandle = <0x6c>;
	};

	cif_isp@ff910000 {
		compatible = "rockchip,rk3288-cif-isp";
		rockchip,grf = <0x4a>;
		reg = <0x00 0xff910000 0x00 0x4000 0x00 0xff968000 0x00 0x4000>;
		reg-names = "register", "csihost-register";
		clocks = <0x07 0xcd 0x07 0x1d5 0x07 0x6b 0x07 0x6c 0x07 0x166 0x07 0x173 0x07 0x7e>;
		clock-names = "aclk_isp", "hclk_isp", "sclk_isp", "sclk_isp_jpe", "pclk_mipi_csi", "pclk_isp_in", "sclk_mipidsi_24m";
		resets = <0x07 0x6e>;
		reset-names = "rst_isp";
		interrupts = <0x00 0x0e 0x04>;
		interrupt-names = "cif_isp10_irq";
		power-domains = <0x6d 0x09>;
		rockchip,isp,iommu-enable = <0x01>;
		iommus = <0x6e>;
		status = "disabled";
		rockchip,camera-modules-attached = <0x6f>;
	};

	isp@ff910000 {
		compatible = "rockchip,rk3288-isp", "rockchip,isp";
		reg = <0x00 0xff910000 0x00 0x4000>;
		interrupts = <0x00 0x0e 0x04>;
		power-domains = <0x6d 0x09>;
		clocks = <0x07 0xcd 0x07 0x1d5 0x07 0x6b 0x07 0x6c 0x07 0x173 0x07 0x7f 0x07 0x7e 0x07 0x7f 0x07 0x166>;
		clock-names = "aclk_isp", "hclk_isp", "clk_isp", "clk_isp_jpe", "pclkin_isp", "clk_cif_out", "clk_mipi_24m", "clk_cif_pll", "hclk_mipiphy1";
		pinctrl-names = "default", "isp_dvp8bit2", "isp_dvp10bit", "isp_dvp12bit", "isp_dvp8bit0", "isp_mipi_fl", "isp_mipi_fl_prefl", "isp_flash_as_gpio", "isp_flash_as_trigger_out";
		pinctrl-0 = <0x70>;
		pinctrl-1 = <0x70 0x71>;
		pinctrl-2 = <0x70 0x71 0x72>;
		pinctrl-3 = <0x70 0x71 0x72 0x73>;
		pinctrl-4 = <0x70 0x74>;
		pinctrl-5 = <0x70>;
		pinctrl-6 = <0x70 0x75>;
		pinctrl-7 = <0x76>;
		pinctrl-8 = <0x77>;
		rockchip,isp,mipiphy = <0x02>;
		rockchip,isp,cifphy = <0x01>;
		rockchip,isp,mipiphy1,reg = <0xff968000 0x4000>;
		rockchip,grf = <0x4a>;
		rockchip,cru = <0x07>;
		rockchip,gpios = <0x3f 0x0d 0x00>;
		rockchip,isp,iommu_enable = <0x01>;
		iommus = <0x6e>;
		status = "okay";
	};

	iommu@ff914000 {
		compatible = "rockchip,iommu";
		reg = <0x00 0xff914000 0x00 0x100 0x00 0xff915000 0x00 0x100>;
		interrupts = <0x00 0x0e 0x04>;
		interrupt-names = "isp_mmu";
		clocks = <0x07 0xcd 0x07 0x1d5>;
		clock-names = "aclk", "hclk";
		rk_iommu,disable_reset_quirk;
		#iommu-cells = <0x00>;
		power-domains = <0x6d 0x09>;
		status = "okay";
		phandle = <0x6e>;
	};

	rga@ff920000 {
		compatible = "rockchip,rga2";
		reg = <0x00 0xff920000 0x00 0x180>;
		interrupts = <0x00 0x12 0x04>;
		clocks = <0x07 0xc8 0x07 0x1d6 0x07 0x6a>;
		clock-names = "aclk_rga", "hclk_rga", "clk_rga";
		power-domains = <0x6d 0x09>;
		resets = <0x07 0x69 0x07 0x6c 0x07 0x6d>;
		reset-names = "core", "axi", "ahb";
		status = "okay";
		dma-coherent;
	};

	vop@ff930000 {
		compatible = "rockchip,rk3288-vop-big";
		rockchip,grf = <0x4a>;
		reg = <0x00 0xff930000 0x00 0x19c 0x00 0xff931000 0x00 0x1000>;
		reg-names = "regs", "gamma_lut";
		interrupts = <0x00 0x0f 0x04>;
		clocks = <0x07 0xc5 0x07 0xbe 0x07 0x1d1>;
		clock-names = "aclk_vop", "dclk_vop", "hclk_vop";
		power-domains = <0x6d 0x09>;
		resets = <0x07 0x64 0x07 0x65 0x07 0x66>;
		reset-names = "axi", "ahb", "dclk";
		iommus = <0x78>;
		status = "okay";

		port {
			#address-cells = <0x01>;
			#size-cells = <0x00>;
			phandle = <0x0f>;

			endpoint@0 {
				reg = <0x00>;
				remote-endpoint = <0x79>;
				phandle = <0x15>;
			};

			endpoint@1 {
				reg = <0x01>;
				remote-endpoint = <0x7a>;
				phandle = <0x8b>;
			};

			endpoint@2 {
				reg = <0x02>;
				remote-endpoint = <0x7b>;
				phandle = <0x13>;
			};

			endpoint@3 {
				reg = <0x03>;
				remote-endpoint = <0x7c>;
				phandle = <0x8d>;
			};

			endpoint@4 {
				reg = <0x04>;
				remote-endpoint = <0x7d>;
				phandle = <0x88>;
			};
		};
	};

	iommu@ff930300 {
		compatible = "rockchip,iommu";
		reg = <0x00 0xff930300 0x00 0x100>;
		interrupts = <0x00 0x0f 0x04>;
		interrupt-names = "vopb_mmu";
		clocks = <0x07 0xc5 0x07 0x1d1>;
		clock-names = "aclk", "hclk";
		power-domains = <0x6d 0x09>;
		#iommu-cells = <0x00>;
		status = "okay";
		phandle = <0x78>;
	};

	vop@ff940000 {
		compatible = "rockchip,rk3288-vop-lit";
		rockchip,grf = <0x4a>;
		reg = <0x00 0xff940000 0x00 0x19c 0x00 0xff941000 0x00 0x1000>;
		reg-names = "regs", "gamma_lut";
		interrupts = <0x00 0x10 0x04>;
		clocks = <0x07 0xc6 0x07 0xbf 0x07 0x1d2>;
		clock-names = "aclk_vop", "dclk_vop", "hclk_vop";
		power-domains = <0x6d 0x09>;
		resets = <0x07 0xb0 0x07 0xb1 0x07 0xb2>;
		reset-names = "axi", "ahb", "dclk";
		iommus = <0x7e>;
		status = "okay";

		port {
			#address-cells = <0x01>;
			#size-cells = <0x00>;
			phandle = <0x10>;

			endpoint@0 {
				reg = <0x00>;
				remote-endpoint = <0x7f>;
				phandle = <0x91>;
			};

			endpoint@1 {
				reg = <0x01>;
				remote-endpoint = <0x80>;
				phandle = <0x12>;
			};

			endpoint@2 {
				reg = <0x02>;
				remote-endpoint = <0x81>;
				phandle = <0x84>;
			};

			endpoint@3 {
				reg = <0x03>;
				remote-endpoint = <0x82>;
				phandle = <0x14>;
			};

			endpoint@4 {
				reg = <0x04>;
				remote-endpoint = <0x83>;
				phandle = <0x89>;
			};
		};
	};

	iommu@ff940300 {
		compatible = "rockchip,iommu";
		reg = <0x00 0xff940300 0x00 0x100>;
		interrupts = <0x00 0x10 0x04>;
		interrupt-names = "vopl_mmu";
		clocks = <0x07 0xc6 0x07 0x1d2>;
		clock-names = "aclk", "hclk";
		power-domains = <0x6d 0x09>;
		#iommu-cells = <0x00>;
		status = "okay";
		phandle = <0x7e>;
	};

	cif@ff950000 {
		compatible = "rockchip,cif";
		reg = <0x00 0xff950000 0x00 0x400>;
		interrupts = <0x00 0x0d 0x04>;
		clocks = <0x07 0xcc 0x07 0x1d9 0x07 0x175 0x07 0x7f>;
		clock-names = "aclk_cif0", "hclk_cif0", "cif0_in", "cif0_out";
		resets = <0x07 0x68>;
		reset-names = "rst_cif";
		pinctrl-names = "cif_pin_all";
		pinctrl-0 = <0x70 0x71 0x73>;
		rockchip,grf = <0x4a>;
		rockchip,cru = <0x07>;
		power-domains = <0x6d 0x09>;
		status = "disabled";
	};

	dsi@ff960000 {
		compatible = "rockchip,rk3288-mipi-dsi", "snps,dw-mipi-dsi";
		reg = <0x00 0xff960000 0x00 0x4000>;
		interrupts = <0x00 0x13 0x04>;
		clocks = <0x07 0x7e 0x07 0x164>;
		clock-names = "ref", "pclk";
		resets = <0x07 0x73>;
		reset-names = "apb";
		power-domains = <0x6d 0x09>;
		rockchip,grf = <0x4a>;
		#address-cells = <0x01>;
		#size-cells = <0x00>;
		status = "okay";
		rockchip,lane-rate = <0x320>;

		ports {
			#address-cells = <0x01>;
			#size-cells = <0x00>;

			port {
				#address-cells = <0x01>;
				#size-cells = <0x00>;

				endpoint@0 {
					reg = <0x00>;
					remote-endpoint = <0x13>;
					status = "okay";
					phandle = <0x7b>;
				};

				endpoint@1 {
					reg = <0x01>;
					remote-endpoint = <0x84>;
					status = "disabled";
					phandle = <0x81>;
				};
			};
		};

		panel {
			compatible = "simple-panel-dsi";
			reg = <0x00>;
			backlight = <0x85>;
			reset-gpios = <0x3f 0x02 0x01>;
			power-supply = <0x86>;
			dsi,flags = <0x03>;
			dsi,format = <0x00>;
			dsi,lanes = <0x04>;
			reset-delay-ms = <0x14>;
			init-delay-ms = <0x14>;
			enable-delay-ms = <0x78>;
			prepare-delay-ms = <0x78>;
			status = "okay";
			panel-init-sequence = [15 00 02 e0 00 15 00 02 e1 93 15 00 02 e2 65 15 00 02 e3 f8 15 00 02 80 03 15 00 02 e0 01 15 00 02 00 00 15 00 02 01 6a 15 00 02 03 00 15 00 02 04 6c 15 00 02 17 00 15 00 02 18 d7 15 00 02 19 01 15 00 02 1a 00 15 00 02 1b d7 15 00 02 1c 01 15 00 02 1f 70 15 00 02 20 2d 15 00 02 21 2d 15 00 02 22 7e 15 00 02 35 28 15 00 02 37 19 15 00 02 38 05 15 00 02 39 00 15 00 02 3a 01 15 00 02 3c 7c 15 00 02 3d ff 15 00 02 3e ff 15 00 02 3f 7f 15 00 02 40 06 15 00 02 41 a0 15 00 02 43 1e 15 00 02 44 0b 15 00 02 45 28 15 00 02 55 01 15 00 02 57 a9 15 00 02 59 0a 15 00 02 5a 2e 15 00 02 5b 1a 15 00 02 5c 15 15 00 02 5d 7f 15 00 02 5e 57 15 00 02 5f 43 15 00 02 60 36 15 00 02 61 31 15 00 02 62 22 15 00 02 63 27 15 00 02 64 11 15 00 02 65 2a 15 00 02 66 2a 15 00 02 67 2a 15 00 02 68 49 15 00 02 69 38 15 00 02 6a 40 15 00 02 6b 32 15 00 02 6c 2e 15 00 02 6d 21 15 00 02 6e 10 15 00 02 6f 02 15 00 02 70 7f 15 00 02 71 57 15 00 02 72 43 15 00 02 73 36 15 00 02 74 31 15 00 02 75 22 15 00 02 76 27 15 00 02 77 11 15 00 02 78 2a 15 00 02 79 2a 15 00 02 7a 2a 15 00 02 7b 49 15 00 02 7c 38 15 00 02 7d 40 15 00 02 7e 32 15 00 02 7f 2e 15 00 02 80 21 15 00 02 81 10 15 00 02 82 02 15 00 02 e0 02 15 00 02 00 52 15 00 02 01 55 15 00 02 02 55 15 00 02 03 50 15 00 02 04 77 15 00 02 05 57 15 00 02 06 55 15 00 02 07 4e 15 00 02 08 4c 15 00 02 09 5f 15 00 02 0a 4a 15 00 02 0b 48 15 00 02 0c 55 15 00 02 0d 46 15 00 02 0e 44 15 00 02 0f 40 15 00 02 10 55 15 00 02 11 55 15 00 02 12 55 15 00 02 13 55 15 00 02 14 55 15 00 02 15 55 15 00 02 16 53 15 00 02 17 55 15 00 02 18 55 15 00 02 19 51 15 00 02 1a 77 15 00 02 1b 57 15 00 02 1c 55 15 00 02 1d 4f 15 00 02 1e 4d 15 00 02 1f 5f 15 00 02 20 4b 15 00 02 21 49 15 00 02 22 55 15 00 02 23 47 15 00 02 24 45 15 00 02 25 41 15 00 02 26 55 15 00 02 27 55 15 00 02 28 55 15 00 02 29 55 15 00 02 2a 55 15 00 02 2b 55 15 00 02 2c 13 15 00 02 2d 15 15 00 02 2e 15 15 00 02 2f 01 15 00 02 30 37 15 00 02 31 17 15 00 02 32 15 15 00 02 33 0d 15 00 02 34 0f 15 00 02 35 15 15 00 02 36 05 15 00 02 37 07 15 00 02 38 15 15 00 02 39 09 15 00 02 3a 0b 15 00 02 3b 11 15 00 02 3c 15 15 00 02 3d 15 15 00 02 3e 15 15 00 02 3f 15 15 00 02 40 15 15 00 02 41 15 15 00 02 42 12 15 00 02 43 15 15 00 02 44 15 15 00 02 45 00 15 00 02 46 37 15 00 02 47 17 15 00 02 48 15 15 00 02 49 0c 15 00 02 4a 0e 15 00 02 4b 15 15 00 02 4c 04 15 00 02 4d 06 15 00 02 4e 15 15 00 02 4f 08 15 00 02 50 0a 15 00 02 51 10 15 00 02 52 15 15 00 02 53 15 15 00 02 54 15 15 00 02 55 15 15 00 02 56 15 15 00 02 57 15 15 00 02 58 40 15 00 02 5b 10 15 00 02 5c 06 15 00 02 5d 40 15 00 02 5e 00 15 00 02 5f 00 15 00 02 60 40 15 00 02 61 03 15 00 02 62 04 15 00 02 63 6c 15 00 02 64 6c 15 00 02 65 75 15 00 02 66 08 15 00 02 67 b4 15 00 02 68 08 15 00 02 69 6c 15 00 02 6a 6c 15 00 02 6b 0c 15 00 02 6d 00 15 00 02 6e 00 15 00 02 6f 88 15 00 02 75 bb 15 00 02 76 00 15 00 02 77 05 15 00 02 78 2a 15 00 02 e0 04 15 00 02 09 11 15 00 02 0e 48 15 00 02 2b 2b 15 00 02 2d 03 15 00 02 2e 44 15 00 02 e0 05 15 00 02 12 72 15 00 02 e0 00 15 00 02 e6 02 15 00 02 e7 0c 05 78 01 11 05 14 01 29];

			display-timings {
				native-mode = <0x87>;

				timing0 {
					clock-frequency = <0x40d9900>;
					hactive = <0x320>;
					vactive = <0x500>;
					hback-porch = <0x14>;
					hfront-porch = <0x14>;
					vback-porch = <0x08>;
					vfront-porch = <0x1e>;
					hsync-len = <0x14>;
					vsync-len = <0x04>;
					hsync-active = <0x00>;
					vsync-active = <0x00>;
					de-active = <0x00>;
					pixelclk-active = <0x00>;
					phandle = <0x87>;
				};
			};
		};
	};

	dsi@ff964000 {
		compatible = "rockchip,rk3288-mipi-dsi", "snps,dw-mipi-dsi";
		reg = <0x00 0xff964000 0x00 0x4000>;
		interrupts = <0x00 0x14 0x04>;
		clocks = <0x07 0x7e 0x07 0x165>;
		clock-names = "ref", "pclk";
		resets = <0x07 0x74>;
		reset-names = "apb";
		power-domains = <0x6d 0x09>;
		rockchip,grf = <0x4a>;
		#address-cells = <0x01>;
		#size-cells = <0x00>;
		status = "disabled";

		ports {
			#address-cells = <0x01>;
			#size-cells = <0x00>;

			port {
				#address-cells = <0x01>;
				#size-cells = <0x00>;

				endpoint@0 {
					reg = <0x00>;
					remote-endpoint = <0x88>;
					phandle = <0x7d>;
				};

				endpoint@1 {
					reg = <0x01>;
					remote-endpoint = <0x89>;
					phandle = <0x83>;
				};
			};
		};
	};

	mipi-phy-tx1rx1@ff968000 {
		compatible = "rockchip,rk3288-mipi-dphy";
		reg = <0x00 0xff968000 0x00 0x4000>;
		rockchip,grf = <0x4a>;
		clocks = <0x07 0x7e 0x07 0x166>;
		clock-names = "dphy-ref", "pclk";
		status = "disabled";
	};

	dp@ff970000 {
		compatible = "rockchip,rk3288-dp";
		reg = <0x00 0xff970000 0x00 0x4000>;
		interrupts = <0x00 0x62 0x04>;
		clocks = <0x07 0x69 0x07 0x163>;
		clock-names = "dp", "pclk";
		power-domains = <0x6d 0x09>;
		phys = <0x8a>;
		phy-names = "dp";
		resets = <0x07 0x6f>;
		reset-names = "dp";
		rockchip,grf = <0x4a>;
		status = "disabled";
		force-hpd;

		ports {
			#address-cells = <0x01>;
			#size-cells = <0x00>;

			port@0 {
				reg = <0x00>;
				#address-cells = <0x01>;
				#size-cells = <0x00>;

				endpoint@0 {
					reg = <0x00>;
					remote-endpoint = <0x8b>;
					status = "disabled";
					phandle = <0x7a>;
				};

				endpoint@1 {
					reg = <0x01>;
					remote-endpoint = <0x12>;
					phandle = <0x80>;
				};
			};

			port@1 {
				reg = <0x01>;
				#address-cells = <0x01>;
				#size-cells = <0x00>;

				endpoint {
					reg = <0x00>;
					remote-endpoint = <0x8c>;
					phandle = <0x9c>;
				};
			};
		};
	};

	lvds@ff96c000 {
		compatible = "rockchip,rk3288-lvds";
		reg = <0x00 0xff96c000 0x00 0x4000>;
		clocks = <0x07 0x167>;
		clock-names = "pclk_lvds";
		power-domains = <0x6d 0x09>;
		rockchip,grf = <0x4a>;
		status = "disabled";

		ports {
			#address-cells = <0x01>;
			#size-cells = <0x00>;

			port@0 {
				reg = <0x00>;
				#address-cells = <0x01>;
				#size-cells = <0x00>;

				endpoint@0 {
					reg = <0x00>;
					remote-endpoint = <0x8d>;
					phandle = <0x7c>;
				};

				endpoint@1 {
					reg = <0x01>;
					remote-endpoint = <0x14>;
					phandle = <0x82>;
				};
			};

			port@1 {
				reg = <0x01>;
				#address-cells = <0x01>;
				#size-cells = <0x00>;

				endpoint@0 {
					reg = <0x00>;
					remote-endpoint = <0x8e>;
					phandle = <0x9e>;
				};
			};
		};
	};

	hdmi@ff980000 {
		compatible = "rockchip,rk3288-dw-hdmi";
		reg = <0x00 0xff980000 0x00 0x20000>;
		reg-io-width = <0x04>;
		rockchip,grf = <0x4a>;
		interrupts = <0x00 0x67 0x04>;
		clocks = <0x07 0x168 0x07 0x6d>;
		clock-names = "iahb", "isfr";
		pinctrl-names = "default", "sleep";
		pinctrl-0 = <0x8f>;
		pinctrl-1 = <0x90>;
		power-domains = <0x6d 0x09>;
		status = "okay";
		#address-cells = <0x01>;
		#size-cells = <0x00>;
		#sound-dai-cells = <0x00>;
		phandle = <0xa1>;

		ports {

			port {
				#address-cells = <0x01>;
				#size-cells = <0x00>;

				endpoint@0 {
					reg = <0x00>;
					remote-endpoint = <0x15>;
					phandle = <0x79>;
				};

				endpoint@1 {
					reg = <0x01>;
					remote-endpoint = <0x91>;
					status = "disabled";
					phandle = <0x7f>;
				};
			};
		};
	};

	video-codec@ff9a0000 {
		compatible = "rockchip,rk3288-vpu";
		reg = <0x00 0xff9a0000 0x00 0x800>;
		interrupts = <0x00 0x09 0x04 0x00 0x0a 0x04>;
		interrupt-names = "vepu", "vdpu";
		clocks = <0x07 0xd0 0x07 0x1dc>;
		clock-names = "aclk", "hclk";
		power-domains = <0x6d 0x0c>;
		iommus = <0x92>;
		assigned-clocks = <0x07 0xd0>;
		assigned-clock-rates = <0x17d78400>;
		status = "disabled";
	};

	vpu-service@ff9a0000 {
		compatible = "rockchip,vpu_service";
		reg = <0x00 0xff9a0000 0x00 0x800>;
		interrupts = <0x00 0x09 0x04 0x00 0x0a 0x04>;
		interrupt-names = "irq_enc", "irq_dec";
		clocks = <0x07 0xd0 0x07 0x1dc>;
		clock-names = "aclk_vcodec", "hclk_vcodec";
		power-domains = <0x6d 0x0c>;
		rockchip,grf = <0x4a>;
		resets = <0x07 0x70 0x07 0x71>;
		reset-names = "video_a", "video_h";
		iommus = <0x92>;
		iommu_enabled = <0x01>;
		status = "okay";
		allocator = <0x01>;
	};

	iommu@ff9a0800 {
		compatible = "rockchip,iommu";
		reg = <0x00 0xff9a0800 0x00 0x100>;
		interrupts = <0x00 0x0b 0x04>;
		interrupt-names = "vpu_mmu";
		clocks = <0x07 0xd0 0x07 0x1dc>;
		clock-names = "aclk", "hclk";
		power-domains = <0x6d 0x0c>;
		#iommu-cells = <0x00>;
		phandle = <0x92>;
	};

	hevc-service@ff9c0000 {
		compatible = "rockchip,hevc_service";
		reg = <0x00 0xff9c0000 0x00 0x400>;
		interrupts = <0x00 0x0c 0x04>;
		interrupt-names = "irq_dec";
		clocks = <0x07 0xcf 0x07 0x1db 0x07 0x70 0x07 0x6f>;
		clock-names = "aclk_vcodec", "hclk_vcodec", "clk_core", "clk_cabac";
		assigned-clocks = <0x07 0xcf 0x07 0x1db 0x07 0x70 0x07 0x6f>;
		assigned-clock-rates = <0x17d78400 0x5f5e100 0x11e1a300 0x11e1a300>;
		resets = <0x07 0x9a>;
		reset-names = "video";
		power-domains = <0x6d 0x0b>;
		rockchip,grf = <0x4a>;
		iommus = <0x93>;
		iommu_enabled = <0x01>;
		status = "okay";
		allocator = <0x01>;
	};

	iommu@ff9c0440 {
		compatible = "rockchip,iommu";
		reg = <0x00 0xff9c0440 0x00 0x40 0x00 0xff9c0480 0x00 0x40>;
		interrupts = <0x00 0x6f 0x04>;
		interrupt-names = "hevc_mmu";
		clocks = <0x07 0xcf 0x07 0x1db 0x07 0x70 0x07 0x6f>;
		clock-names = "aclk", "hclk", "clk_core", "clk_cabac";
		power-domains = <0x6d 0x0b>;
		#iommu-cells = <0x00>;
		phandle = <0x93>;
	};

	gpu@ffa30000 {
		compatible = "arm,malit764", "arm,malit76x", "arm,malit7xx", "arm,mali-midgard";
		reg = <0x00 0xffa30000 0x00 0x10000>;
		interrupts = <0x00 0x06 0x04 0x00 0x07 0x04 0x00 0x08 0x04>;
		interrupt-names = "JOB", "MMU", "GPU";
		clocks = <0x07 0xc0>;
		clock-names = "clk_mali";
		operating-points-v2 = <0x94>;
		#cooling-cells = <0x02>;
		power-domains = <0x6d 0x0d>;
		status = "okay";
		upthreshold = <0x4b>;
		downdifferential = <0x0a>;
		mali-supply = <0x95>;
		phandle = <0x48>;

		power_model {
			compatible = "arm,mali-simple-power-model";
			static-coefficient = <0x64578>;
			dynamic-coefficient = <0x2dd>;
			ts = <0x7d00 0x125c 0xffffffb0 0x02>;
			thermal-zone = "gpu-thermal";
		};
	};

	opp-table1 {
		compatible = "operating-points-v2";
		phandle = <0x94>;

		opp-100000000 {
			opp-hz = <0x00 0x5f5e100>;
			opp-microvolt = <0xe7ef0>;
		};

		opp-200000000 {
			opp-hz = <0x00 0xbebc200>;
			opp-microvolt = <0xe7ef0>;
		};

		opp-300000000 {
			opp-hz = <0x00 0x11e1a300>;
			opp-microvolt = <0xf4240>;
		};

		opp-400000000 {
			opp-hz = <0x00 0x17d78400>;
			opp-microvolt = <0x10c8e0>;
		};

		opp-500000000 {
			opp-hz = <0x00 0x1dcd6500>;
			opp-microvolt = <0x124f80>;
		};
	};

	syscon@ffac0000 {
		compatible = "rockchip,rk3288-noc", "syscon";
		reg = <0x00 0xffac0000 0x00 0x2000>;
	};

	nocp-core@ffac0400 {
		compatible = "rockchip,rk3288-nocp";
		reg = <0x00 0xffac0400 0x00 0x400>;
	};

	nocp-gpu@ffac0800 {
		compatible = "rockchip,rk3288-nocp";
		reg = <0x00 0xffac0800 0x00 0x400>;
	};

	nocp-peri@ffac0c00 {
		compatible = "rockchip,rk3288-nocp";
		reg = <0x00 0xffac0c00 0x00 0x400>;
	};

	nocp-vpu@ffac1000 {
		compatible = "rockchip,rk3288-nocp";
		reg = <0x00 0xffac1000 0x00 0x400>;
	};

	nocp-vio0@ffac1400 {
		compatible = "rockchip,rk3288-nocp";
		reg = <0x00 0xffac1400 0x00 0x400>;
	};

	nocp-vio1@ffac1800 {
		compatible = "rockchip,rk3288-nocp";
		reg = <0x00 0xffac1800 0x00 0x400>;
	};

	nocp-vio2@ffac1c00 {
		compatible = "rockchip,rk3288-nocp";
		reg = <0x00 0xffac1c00 0x00 0x400>;
	};

	efuse@ffb40000 {
		compatible = "rockchip,rk3288-secure-efuse";
		reg = <0x00 0xffb40000 0x00 0x20>;
		#address-cells = <0x01>;
		#size-cells = <0x01>;
		clocks = <0x07 0x171>;
		clock-names = "pclk_efuse";

		special-function@5 {
			reg = <0x05 0x01>;
			bits = <0x04 0x04>;
			phandle = <0x0b>;
		};

		process-version@6 {
			reg = <0x06 0x01>;
			bits = <0x00 0x04>;
			phandle = <0x0d>;
		};

		id@7 {
			reg = <0x07 0x10>;
			phandle = <0xa8>;
		};

		cpu-leakage@17 {
			reg = <0x17 0x01>;
			phandle = <0x0a>;
		};

		performance@1c {
			reg = <0x1c 0x01>;
			bits = <0x04 0x03>;
			phandle = <0x0e>;
		};

		performance@1d {
			reg = <0x1d 0x01>;
			bits = <0x04 0x03>;
			phandle = <0x0c>;
		};
	};

	interrupt-controller@ffc01000 {
		compatible = "arm,gic-400";
		interrupt-controller;
		#interrupt-cells = <0x03>;
		#address-cells = <0x00>;
		reg = <0x00 0xffc01000 0x00 0x1000 0x00 0xffc02000 0x00 0x2000 0x00 0xffc04000 0x00 0x2000 0x00 0xffc06000 0x00 0x2000>;
		interrupts = <0x01 0x09 0xf04>;
		phandle = <0x01>;
	};

	pinctrl {
		compatible = "rockchip,rk3288-pinctrl";
		rockchip,grf = <0x4a>;
		rockchip,pmu = <0x06>;
		#address-cells = <0x02>;
		#size-cells = <0x02>;
		ranges;

		gpio0@ff750000 {
			compatible = "rockchip,gpio-bank";
			reg = <0x00 0xff750000 0x00 0x100>;
			interrupts = <0x00 0x51 0x04>;
			clocks = <0x07 0x140>;
			gpio-controller;
			#gpio-cells = <0x02>;
			interrupt-controller;
			#interrupt-cells = <0x02>;
			phandle = <0x3d>;
		};

		gpio1@ff780000 {
			compatible = "rockchip,gpio-bank";
			reg = <0x00 0xff780000 0x00 0x100>;
			interrupts = <0x00 0x52 0x04>;
			clocks = <0x07 0x141>;
			gpio-controller;
			#gpio-cells = <0x02>;
			interrupt-controller;
			#interrupt-cells = <0x02>;
			phandle = <0x38>;
		};

		gpio2@ff790000 {
			compatible = "rockchip,gpio-bank";
			reg = <0x00 0xff790000 0x00 0x100>;
			interrupts = <0x00 0x53 0x04>;
			clocks = <0x07 0x142>;
			gpio-controller;
			#gpio-cells = <0x02>;
			interrupt-controller;
			#interrupt-cells = <0x02>;
			phandle = <0x3c>;
		};

		gpio3@ff7a0000 {
			compatible = "rockchip,gpio-bank";
			reg = <0x00 0xff7a0000 0x00 0x100>;
			interrupts = <0x00 0x54 0x04>;
			clocks = <0x07 0x143>;
			gpio-controller;
			#gpio-cells = <0x02>;
			interrupt-controller;
			#interrupt-cells = <0x02>;
		};

		gpio4@ff7b0000 {
			compatible = "rockchip,gpio-bank";
			reg = <0x00 0xff7b0000 0x00 0x100>;
			interrupts = <0x00 0x55 0x04>;
			clocks = <0x07 0x144>;
			gpio-controller;
			#gpio-cells = <0x02>;
			interrupt-controller;
			#interrupt-cells = <0x02>;
			phandle = <0x4c>;
		};

		gpio5@ff7c0000 {
			compatible = "rockchip,gpio-bank";
			reg = <0x00 0xff7c0000 0x00 0x100>;
			interrupts = <0x00 0x56 0x04>;
			clocks = <0x07 0x145>;
			gpio-controller;
			#gpio-cells = <0x02>;
			interrupt-controller;
			#interrupt-cells = <0x02>;
		};

		gpio6@ff7d0000 {
			compatible = "rockchip,gpio-bank";
			reg = <0x00 0xff7d0000 0x00 0x100>;
			interrupts = <0x00 0x57 0x04>;
			clocks = <0x07 0x146>;
			gpio-controller;
			#gpio-cells = <0x02>;
			interrupt-controller;
			#interrupt-cells = <0x02>;
			phandle = <0x53>;
		};

		gpio7@ff7e0000 {
			compatible = "rockchip,gpio-bank";
			reg = <0x00 0xff7e0000 0x00 0x100>;
			interrupts = <0x00 0x58 0x04>;
			clocks = <0x07 0x147>;
			gpio-controller;
			#gpio-cells = <0x02>;
			interrupt-controller;
			#interrupt-cells = <0x02>;
			phandle = <0x3f>;
		};

		gpio8@ff7f0000 {
			compatible = "rockchip,gpio-bank";
			reg = <0x00 0xff7f0000 0x00 0x100>;
			interrupts = <0x00 0x59 0x04>;
			clocks = <0x07 0x148>;
			gpio-controller;
			#gpio-cells = <0x02>;
			interrupt-controller;
			#interrupt-cells = <0x02>;
			phandle = <0xa2>;
		};

		hdmi {

			hdmi-gpio {
				rockchip,pins = <0x07 0x13 0x00 0x96 0x07 0x14 0x00 0x96>;
				phandle = <0x90>;
			};

			hdmi-ddc {
				rockchip,pins = <0x07 0x13 0x02 0x96 0x07 0x14 0x02 0x96>;
				phandle = <0x8f>;
			};
		};

		pcfg-pull-up {
			bias-pull-up;
			phandle = <0x97>;
		};

		pcfg-pull-down {
			bias-pull-down;
			phandle = <0x98>;
		};

		pcfg-pull-none {
			bias-disable;
			phandle = <0x96>;
		};

		pcfg-pull-none-12ma {
			bias-disable;
			drive-strength = <0x0c>;
			phandle = <0x9b>;
		};

		sleep {

			global-pwroff {
				rockchip,pins = <0x00 0x00 0x01 0x96>;
			};

			ddrio-pwroff {
				rockchip,pins = <0x00 0x01 0x01 0x96>;
			};

			ddr0-retention {
				rockchip,pins = <0x00 0x02 0x01 0x97>;
			};

			ddr1-retention {
				rockchip,pins = <0x00 0x03 0x01 0x97>;
			};
		};

		edp {

			edp-hpd {
				rockchip,pins = <0x07 0x0b 0x02 0x98>;
			};
		};

		i2c0 {

			i2c0-xfer {
				rockchip,pins = <0x00 0x0f 0x01 0x96 0x00 0x10 0x01 0x96>;
				phandle = <0x33>;
			};
		};

		i2c1 {

			i2c1-xfer {
				rockchip,pins = <0x08 0x04 0x01 0x96 0x08 0x05 0x01 0x96>;
				phandle = <0x37>;
			};
		};

		i2c2 {

			i2c2-xfer {
				rockchip,pins = <0x06 0x09 0x01 0x96 0x06 0x0a 0x01 0x96>;
				phandle = <0x52>;
			};
		};

		i2c3 {

			i2c3-xfer {
				rockchip,pins = <0x02 0x10 0x01 0x96 0x02 0x11 0x01 0x96>;
				phandle = <0x39>;
			};
		};

		i2c4 {

			i2c4-xfer {
				rockchip,pins = <0x07 0x11 0x01 0x96 0x07 0x12 0x01 0x96>;
				phandle = <0x3e>;
			};
		};

		i2c5 {

			i2c5-xfer {
				rockchip,pins = <0x07 0x13 0x01 0x96 0x07 0x14 0x01 0x96>;
				phandle = <0x40>;
			};
		};

		i2s0 {

			i2s0-bus {
				rockchip,pins = <0x06 0x00 0x01 0x96 0x06 0x01 0x01 0x96 0x06 0x02 0x01 0x96 0x06 0x03 0x01 0x96 0x06 0x04 0x01 0x96>;
				phandle = <0x6b>;
			};

			i2s0-mclk {
				rockchip,pins = <0x06 0x08 0x01 0x96>;
				phandle = <0x54>;
			};
		};

		lcdc {

			lcdc-ctl {
				rockchip,pins = <0x01 0x18 0x01 0x96 0x01 0x19 0x01 0x96 0x01 0x1a 0x01 0x96 0x01 0x1b 0x01 0x96>;
			};
		};

		sdmmc {

			sdmmc-clk {
				rockchip,pins = <0x06 0x14 0x01 0x99>;
				phandle = <0x16>;
			};

			sdmmc-cmd {
				rockchip,pins = <0x06 0x15 0x01 0x9a>;
				phandle = <0x17>;
			};

			sdmmc-cd {
				rockchip,pins = <0x06 0x16 0x01 0x97>;
				phandle = <0x18>;
			};

			sdmmc-bus1 {
				rockchip,pins = <0x06 0x10 0x01 0x97>;
			};

			sdmmc-bus4 {
				rockchip,pins = <0x06 0x10 0x01 0x9a 0x06 0x11 0x01 0x9a 0x06 0x12 0x01 0x9a 0x06 0x13 0x01 0x9a>;
				phandle = <0x19>;
			};

			sdmmc-pwr {
				rockchip,pins = <0x07 0x0b 0x00 0x96>;
				phandle = <0xa5>;
			};
		};

		sdio0 {

			sdio0-bus1 {
				rockchip,pins = <0x04 0x14 0x01 0x97>;
			};

			sdio0-bus4 {
				rockchip,pins = <0x04 0x14 0x01 0x97 0x04 0x15 0x01 0x97 0x04 0x16 0x01 0x97 0x04 0x17 0x01 0x97>;
				phandle = <0x1d>;
			};

			sdio0-cmd {
				rockchip,pins = <0x04 0x18 0x01 0x97>;
				phandle = <0x1e>;
			};

			sdio0-clk {
				rockchip,pins = <0x04 0x19 0x01 0x96>;
				phandle = <0x1f>;
			};

			sdio0-cd {
				rockchip,pins = <0x04 0x1a 0x01 0x97>;
			};

			sdio0-wp {
				rockchip,pins = <0x04 0x1b 0x01 0x97>;
			};

			sdio0-pwr {
				rockchip,pins = <0x04 0x1c 0x01 0x97>;
			};

			sdio0-bkpwr {
				rockchip,pins = <0x04 0x1d 0x01 0x97>;
			};

			sdio0-int {
				rockchip,pins = <0x04 0x1e 0x01 0x97>;
				phandle = <0x20>;
			};
		};

		sdio1 {

			sdio1-bus1 {
				rockchip,pins = <0x03 0x18 0x04 0x97>;
			};

			sdio1-bus4 {
				rockchip,pins = <0x03 0x18 0x04 0x97 0x03 0x19 0x04 0x97 0x03 0x1a 0x04 0x97 0x03 0x1b 0x04 0x97>;
			};

			sdio1-cd {
				rockchip,pins = <0x03 0x1c 0x04 0x97>;
			};

			sdio1-wp {
				rockchip,pins = <0x03 0x1d 0x04 0x97>;
			};

			sdio1-bkpwr {
				rockchip,pins = <0x03 0x1e 0x04 0x97>;
			};

			sdio1-int {
				rockchip,pins = <0x03 0x1f 0x04 0x97>;
			};

			sdio1-cmd {
				rockchip,pins = <0x04 0x06 0x04 0x97>;
			};

			sdio1-clk {
				rockchip,pins = <0x04 0x07 0x04 0x96>;
			};

			sdio1-pwr {
				rockchip,pins = <0x04 0x09 0x04 0x97>;
			};
		};

		emmc {

			emmc-clk {
				rockchip,pins = <0x03 0x12 0x02 0x96>;
				phandle = <0x21>;
			};

			emmc-cmd {
				rockchip,pins = <0x03 0x10 0x02 0x97>;
				phandle = <0x22>;
			};

			emmc-pwr {
				rockchip,pins = <0x03 0x09 0x02 0x97>;
				phandle = <0x23>;
			};

			emmc-bus1 {
				rockchip,pins = <0x03 0x00 0x02 0x97>;
			};

			emmc-bus4 {
				rockchip,pins = <0x03 0x00 0x02 0x97 0x03 0x01 0x02 0x97 0x03 0x02 0x02 0x97 0x03 0x03 0x02 0x97>;
			};

			emmc-bus8 {
				rockchip,pins = <0x03 0x00 0x02 0x97 0x03 0x01 0x02 0x97 0x03 0x02 0x02 0x97 0x03 0x03 0x02 0x97 0x03 0x04 0x02 0x97 0x03 0x05 0x02 0x97 0x03 0x06 0x02 0x97 0x03 0x07 0x02 0x97>;
				phandle = <0x24>;
			};
		};

		spi0 {

			spi0-clk {
				rockchip,pins = <0x05 0x0c 0x01 0x97>;
				phandle = <0x27>;
			};

			spi0-cs0 {
				rockchip,pins = <0x05 0x0d 0x01 0x97>;
				phandle = <0x2a>;
			};

			spi0-tx {
				rockchip,pins = <0x05 0x0e 0x01 0x97>;
				phandle = <0x28>;
			};

			spi0-rx {
				rockchip,pins = <0x05 0x0f 0x01 0x97>;
				phandle = <0x29>;
			};

			spi0-cs1 {
				rockchip,pins = <0x05 0x10 0x01 0x97>;
			};
		};

		spi1 {

			spi1-clk {
				rockchip,pins = <0x07 0x0c 0x02 0x97>;
				phandle = <0x2b>;
			};

			spi1-cs0 {
				rockchip,pins = <0x07 0x0d 0x02 0x97>;
				phandle = <0x2e>;
			};

			spi1-rx {
				rockchip,pins = <0x07 0x0e 0x02 0x97>;
				phandle = <0x2d>;
			};

			spi1-tx {
				rockchip,pins = <0x07 0x0f 0x02 0x97>;
				phandle = <0x2c>;
			};
		};

		spi2 {

			spi2-cs1 {
				rockchip,pins = <0x08 0x03 0x01 0x97>;
			};

			spi2-clk {
				rockchip,pins = <0x08 0x06 0x01 0x97>;
				phandle = <0x2f>;
			};

			spi2-cs0 {
				rockchip,pins = <0x08 0x07 0x01 0x97>;
				phandle = <0x32>;
			};

			spi2-rx {
				rockchip,pins = <0x08 0x08 0x01 0x97>;
				phandle = <0x31>;
			};

			spi2-tx {
				rockchip,pins = <0x08 0x09 0x01 0x97>;
				phandle = <0x30>;
			};
		};

		uart0 {

			uart0-xfer {
				rockchip,pins = <0x04 0x10 0x01 0x97 0x04 0x11 0x01 0x96>;
				phandle = <0x41>;
			};

			uart0-cts {
				rockchip,pins = <0x04 0x12 0x01 0x97>;
				phandle = <0x42>;
			};

			uart0-rts {
				rockchip,pins = <0x04 0x13 0x01 0x96>;
				phandle = <0xa6>;
			};
		};

		uart1 {

			uart1-xfer {
				rockchip,pins = <0x05 0x08 0x01 0x97 0x05 0x09 0x01 0x96>;
				phandle = <0x43>;
			};

			uart1-cts {
				rockchip,pins = <0x05 0x0a 0x01 0x97>;
			};

			uart1-rts {
				rockchip,pins = <0x05 0x0b 0x01 0x96>;
			};
		};

		uart2 {

			uart2_xfer: uart2-xfer {
				rockchip,pins = <0x07 0x16 0x01 0x97 0x07 0x17 0x01 0x96>;
			};
		};

		uart3 {

			uart3-xfer {
				rockchip,pins = <0x07 0x07 0x01 0x97 0x07 0x08 0x01 0x96>;
				phandle = <0x44>;
			};

			uart3-cts {
				rockchip,pins = <0x07 0x09 0x01 0x97>;
			};

			uart3-rts {
				rockchip,pins = <0x07 0x0a 0x01 0x96>;
			};
		};

		uart4 {

			uart4-xfer {
				rockchip,pins = <0x05 0x0f 0x03 0x97 0x05 0x0e 0x03 0x96>;
				phandle = <0x45>;
			};

			uart4-cts {
				rockchip,pins = <0x05 0x0c 0x03 0x97>;
			};

			uart4-rts {
				rockchip,pins = <0x05 0x0d 0x03 0x96>;
			};
		};

		tsadc {

			otp-gpio {
				rockchip,pins = <0x00 0x0a 0x00 0x96>;
				phandle = <0x49>;
			};

			otp-out {
				rockchip,pins = <0x00 0x0a 0x01 0x96>;
			};
		};

		pwm0 {

			pwm0-pin {
				rockchip,pins = <0x07 0x00 0x01 0x96>;
				phandle = <0x55>;
			};

			pwm0-pin-pull-down {
				rockchip,pins = <0x07 0x00 0x01 0x98>;
			};
		};

		pwm1 {

			pwm1-pin {
				rockchip,pins = <0x07 0x01 0x01 0x96>;
				phandle = <0x56>;
			};

			pwm1-pin-pull-down {
				rockchip,pins = <0x07 0x01 0x01 0x98>;
			};
		};

		pwm2 {

			pwm2-pin {
				rockchip,pins = <0x07 0x16 0x03 0x96>;
				phandle = <0x57>;
			};

			pwm2-pin-pull-down {
				rockchip,pins = <0x07 0x16 0x03 0x98>;
			};
		};

		pwm3 {

			pwm3-pin {
				rockchip,pins = <0x07 0x17 0x03 0x96>;
				phandle = <0x58>;
			};

			pwm3-pin-pull-down {
				rockchip,pins = <0x07 0x17 0x03 0x98>;
			};
		};

		gmac {

			rgmii-pins {
				rockchip,pins = <0x03 0x1e 0x03 0x96 0x03 0x1f 0x03 0x96 0x03 0x1a 0x03 0x96 0x03 0x1b 0x03 0x96 0x03 0x1c 0x03 0x9b 0x03 0x1d 0x03 0x9b 0x03 0x18 0x03 0x9b 0x03 0x19 0x03 0x9b 0x04 0x00 0x03 0x96 0x04 0x05 0x03 0x96 0x04 0x06 0x03 0x96 0x04 0x09 0x03 0x9b 0x04 0x04 0x03 0x9b 0x04 0x01 0x03 0x96 0x04 0x03 0x03 0x96>;
				phandle = <0x4e>;
			};

			rmii-pins {
				rockchip,pins = <0x03 0x1e 0x03 0x96 0x03 0x1f 0x03 0x96 0x03 0x1c 0x03 0x96 0x03 0x1d 0x03 0x96 0x04 0x00 0x03 0x96 0x04 0x05 0x03 0x96 0x04 0x04 0x03 0x96 0x04 0x01 0x03 0x96 0x04 0x02 0x03 0x96 0x04 0x03 0x03 0x96>;
			};
		};

		spdif {

			spdif-tx {
				rockchip,pins = <0x06 0x0b 0x01 0x96>;
				phandle = <0x6a>;
			};
		};

		cif {

			cif-dvp-d2d9 {
				rockchip,pins = <0x02 0x00 0x01 0x96 0x02 0x01 0x01 0x96 0x02 0x02 0x01 0x96 0x02 0x03 0x01 0x96 0x02 0x04 0x01 0x96 0x02 0x05 0x01 0x96 0x02 0x06 0x01 0x96 0x02 0x07 0x01 0x96 0x02 0x08 0x01 0x96 0x02 0x09 0x01 0x96 0x02 0x0b 0x01 0x96>;
			};
		};

		isp_pin {

			isp-mipi {
				rockchip,pins = <0x02 0x0b 0x01 0x96>;
				phandle = <0x70>;
			};

			isp-d2d9 {
				rockchip,pins = <0x02 0x00 0x01 0x96 0x02 0x01 0x01 0x96 0x02 0x02 0x01 0x96 0x02 0x03 0x01 0x96 0x02 0x04 0x01 0x96 0x02 0x05 0x01 0x96 0x02 0x06 0x01 0x96 0x02 0x07 0x01 0x96 0x02 0x08 0x01 0x96 0x02 0x09 0x01 0x96 0x02 0x0a 0x01 0x96 0x02 0x0b 0x01 0x96>;
				phandle = <0x71>;
			};

			isp-d0d1 {
				rockchip,pins = <0x02 0x0c 0x01 0x96 0x02 0x0d 0x01 0x96>;
				phandle = <0x72>;
			};

			isp-d10d11 {
				rockchip,pins = <0x02 0x0e 0x01 0x96 0x02 0x0f 0x01 0x96>;
				phandle = <0x73>;
			};

			isp-d0d7 {
				rockchip,pins = <0x02 0x0c 0x01 0x96 0x02 0x0d 0x01 0x96 0x02 0x00 0x01 0x96 0x02 0x01 0x01 0x96 0x02 0x02 0x01 0x96 0x02 0x03 0x01 0x96 0x02 0x04 0x01 0x96 0x02 0x05 0x01 0x96>;
				phandle = <0x74>;
			};

			isp-shutter {
				rockchip,pins = <0x07 0x0c 0x02 0x96 0x07 0x0f 0x02 0x96>;
			};

			isp-flash-trigger {
				rockchip,pins = <0x07 0x0d 0x02 0x96>;
				phandle = <0x77>;
			};

			isp-prelight {
				rockchip,pins = <0x07 0x0e 0x02 0x96>;
				phandle = <0x75>;
			};

			isp-flash-trigger-as-gpio {
				rockchip,pins = <0x07 0x0d 0x02 0x96>;
				phandle = <0x76>;
			};
		};

		pcfg-pull-none-drv-8ma {
			drive-strength = <0x08>;
			phandle = <0x99>;
		};

		pcfg-pull-up-drv-8ma {
			bias-pull-up;
			drive-strength = <0x08>;
			phandle = <0x9a>;
		};

		pmic {

			pmic-int {
				rockchip,pins = <0x00 0x04 0x00 0x97>;
			};
		};

		sdio-pwrseq {

			wifi-enable-h {
				rockchip,pins = <0x04 0x1c 0x00 0x96>;
				phandle = <0xb4>;
			};
		};

		usb {

			host-vbus-drv {
				rockchip,pins = <0x08 0x09 0x00 0x96>;
				phandle = <0xa3>;
			};
		};

		eth_phy {

			eth-phy-pwr {
				rockchip,pins = <0x00 0x06 0x00 0x96>;
				phandle = <0xa4>;
			};
		};

		lcd {

			lcd-cs {
				rockchip,pins = <0x07 0x04 0x00 0x96>;
				phandle = <0x9d>;
			};

			lcd-en {
				rockchip,pins = <0x07 0x03 0x00 0x96>;
				phandle = <0xb5>;
			};
		};

		wireless-bluetooth {

			uart0-gpios {
				rockchip,pins = <0x04 0x13 0x00 0x96>;
				phandle = <0xa7>;
			};
		};

		backlight {

			bl-en {
				rockchip,pins = <0x07 0x09 0x00 0x96>;
				phandle = <0xb1>;
			};
		};

		buttons {

			pwrbtn {
				rockchip,pins = <0x00 0x05 0x00 0x97>;
				phandle = <0xaf>;
			};
		};

		cam_pins {

			cam0-default-pins {
				rockchip,pins = <0x00 0x11 0x00 0x96 0x02 0x0f 0x00 0x96 0x02 0x0b 0x01 0x96>;
				phandle = <0x3a>;
			};

			cam0-sleep-pins {
				rockchip,pins = <0x00 0x11 0x00 0x96 0x02 0x0f 0x00 0x96 0x02 0x0b 0x00 0x96>;
				phandle = <0x3b>;
			};
		};

		wifi {

			wifi-pwr {
				rockchip,pins = <0x04 0x1c 0x00 0x96>;
				phandle = <0xb6>;
			};
		};

		mpu6050 {

			mpu6050-irq-gpio {
				rockchip,pins = <0x08 0x00 0x00 0x96>;
			};
		};
	};

	rockchip-suspend {
		compatible = "rockchip,pm-rk3288";
		status = "okay";
		rockchip,sleep-mode-config = <0x80207>;
		rockchip,wakeup-config = <0x08>;
		rockchip,pwm-regulator-config = <0x04>;
	};

	edp-panel {
		status = "disabled";

		ports {

			endpoint {
				remote-endpoint = <0x9c>;
				phandle = <0x8c>;
			};
		};
	};

	lvds-panel {
		status = "disabled";
		pinctrl-0 = <0x9d>;
		power-supply = <0x86>;

		ports {

			endpoint {
				remote-endpoint = <0x9e>;
				phandle = <0x8e>;
			};
		};
	};

	sound {
		status = "okay";
		compatible = "simple-audio-card";
		simple-audio-card,format = "i2s";
		simple-audio-card,name = "rockchip,es8316-codec";
		simple-audio-card,mclk-fs = <0x200>;
		simple-audio-card,widgets = "Microphone", "Microphone Jack", "Headphone", "Headphone Jack";
		simple-audio-card,routing = "MIC1", "Microphone Jack", "MIC2", "Microphone Jack", "Microphone Jack", "micbias1", "Headphone Jack", "HPOL", "Headphone Jack", "HPOR";

		simple-audio-card,dai-link@0 {
			format = "i2s";

			cpu {
				sound-dai = <0x9f>;
			};

			codec {
				sound-dai = <0xa0>;
			};
		};

		simple-audio-card,dai-link@1 {
			format = "i2s";

			cpu {
				sound-dai = <0x9f>;
			};

			codec {
				sound-dai = <0xa1>;
			};
		};
	};

	external-gmac-clock {
		compatible = "fixed-clock";
		clock-frequency = <0x7735940>;
		clock-output-names = "ext_gmac";
		#clock-cells = <0x00>;
		phandle = <0x4d>;
	};

	vccadc-ref {
		compatible = "regulator-fixed";
		regulator-name = "vcc1v8_sys";
		regulator-always-on;
		regulator-boot-on;
		regulator-min-microvolt = <0x1b7740>;
		regulator-max-microvolt = <0x1b7740>;
		phandle = <0x25>;
	};

	vcc-host-regulator {
		compatible = "regulator-fixed";
		enable-active-high;
		gpio = <0xa2 0x09 0x00>;
		pinctrl-names = "default";
		pinctrl-0 = <0xa3>;
		regulator-name = "vcc_host";
		regulator-always-on;
		regulator-boot-on;
	};

	vcc-phy-regulator {
		compatible = "regulator-fixed";
		enable-active-high;
		pinctrl-names = "default";
		pinctrl-0 = <0xa4>;
		regulator-name = "vcc_phy";
		regulator-min-microvolt = <0x325aa0>;
		regulator-max-microvolt = <0x325aa0>;
		regulator-always-on;
		regulator-boot-on;
		phandle = <0x4b>;
	};

	vsys-regulator {
		compatible = "regulator-fixed";
		regulator-name = "vcc_sys";
		regulator-min-microvolt = <0x4c4b40>;
		regulator-max-microvolt = <0x4c4b40>;
		regulator-always-on;
		regulator-boot-on;
		phandle = <0x34>;
	};

	sdmmc-regulator {
		compatible = "regulator-fixed";
		gpio = <0x3f 0x0b 0x01>;
		pinctrl-names = "default";
		pinctrl-0 = <0xa5>;
		regulator-name = "vcc_sd";
		regulator-min-microvolt = <0x325aa0>;
		regulator-max-microvolt = <0x325aa0>;
		startup-delay-us = <0x186a0>;
		vin-supply = <0x35>;
		phandle = <0x1a>;
	};

	wireless-bluetooth {
		compatible = "bluetooth-platdata";
		uart_rts_gpios = <0x4c 0x13 0x01>;
		pinctrl-names = "default", "rts_gpio";
		pinctrl-0 = <0xa6>;
		pinctrl-1 = <0xa7>;
		BT,reset_gpio = <0x4c 0x1d 0x00>;
		BT,wake_gpio = <0x4c 0x1a 0x00>;
		BT,wake_host_irq = <0x4c 0x1f 0x00>;
		status = "okay";
	};

	wireless-wlan {
		compatible = "wlan-platdata";
		rockchip,grf = <0x4a>;
		wifi_chip_type = "ap6212";
		sdio_vref = <0x708>;
		WIFI,host_wake_irq = <0x4c 0x1e 0x00>;
		status = "okay";
	};

	ddr_timing {
		compatible = "rockchip,ddr-timing";
		ddr3_speed_bin = <0x15>;
		pd_idle = <0x40>;
		sr_idle = <0x01>;
		auto_pd_dis_freq = <0x320>;
		auto_sr_dis_freq = <0x320>;
		ddr3_dll_dis_freq = <0x12c>;
		phy_dll_dis_freq = <0xfa>;
		ddr3_odt_dis_freq = <0x14d>;
		phy_ddr3_odt_dis_freq = <0x14d>;
		ddr3_drv = <0x28>;
		ddr3_odt = <0x78>;
		phy_ddr3_drv = <0x19>;
		phy_ddr3_odt = <0x02>;
		lpddr2_drv = <0x28>;
		phy_lpddr2_drv = <0x1b>;
		lpddr3_odt_dis_freq = <0x14d>;
		phy_lpddr3_odt_dis_freq = <0x14d>;
		lpddr3_drv = <0x28>;
		lpddr3_odt = <0xf0>;
		phy_lpddr3_drv = <0x1b>;
		phy_lpddr3_odt = <0x02>;
		phandle = <0xab>;
	};

	firmware {

		android {
			compatible = "android,firmware";

			fstab {
				compatible = "android,fstab";

				system {
					compatible = "android,system";
					dev = "/dev/block/by-name/system";
					type = "ext4";
					mnt_flags = "ro,barrier=1,inode_readahead_blks=8";
					fsmgr_flags = "wait";
				};

				vendor {
					compatible = "android,vendor";
					dev = "/dev/block/by-name/vendor";
					type = "ext4";
					mnt_flags = "ro,barrier=1,inode_readahead_blks=8";
					fsmgr_flags = "wait";
				};
			};
		};
	};

	cpuinfo {
		compatible = "rockchip,cpuinfo";
		nvmem-cells = <0xa8>;
		nvmem-cell-names = "id";
	};

	dfi {
		compatible = "rockchip,rk3288-dfi";
		rockchip,pmu = <0x06>;
		rockchip,grf = <0x4a>;
		status = "okay";
		phandle = <0xa9>;
	};

	dmc {
		compatible = "rockchip,rk3288-dmc";
		devfreq-events = <0xa9>;
		clocks = <0x07 0x80 0x07 0x16d 0x07 0x16c 0x07 0x16f 0x07 0x16e>;
		clock-names = "dmc_clk", "pclk_phy0", "pclk_upctl0", "pclk_phy1", "pclk_upctl1";
		upthreshold = <0x37>;
		downdifferential = <0x0a>;
		operating-points-v2 = <0xaa>;
		vop-dclk-mode = <0x01>;
		min-cpu-freq = <0x927c0>;
		rockchip,ddr_timing = <0xab>;
		system-status-freq = <0x01 0x60ae0 0x08 0x60ae0 0x02 0x2ee00 0x20 0x493e0 0x10 0x60ae0 0x10000 0x80e80 0x2000 0x80e80 0x1000 0x60ae0 0xc00 0x60ae0 0x4000 0x60ae0>;
		auto-min-freq = <0x60ae0>;
		auto-freq-en = <0x00>;
		status = "okay";
		center-supply = <0xac>;
	};

	opp_table2 {
		compatible = "operating-points-v2";
		phandle = <0xaa>;

		opp-192000000 {
			opp-hz = <0x00 0xb71b000>;
			opp-microvolt = <0x10c8e0>;
		};

		opp-300000000 {
			opp-hz = <0x00 0x11e1a300>;
			opp-microvolt = <0x10c8e0>;
		};

		opp-396000000 {
			opp-hz = <0x00 0x179a7b00>;
			opp-microvolt = <0x10c8e0>;
		};

		opp-528000000 {
			opp-hz = <0x00 0x1f78a400>;
			opp-microvolt = <0x118c30>;
		};
	};

	ramoops {
		compatible = "ramoops";
		record-size = <0x00 0x20000>;
		console-size = <0x00 0x80000>;
		ftrace-size = <0x00 0x00>;
		pmsg-size = <0x00 0x50000>;
		memory-region = <0xad>;
	};

	fiq-debugger {
		compatible = "rockchip,fiq-debugger";
		interrupts = <0x00 0x9b 0x04>;
		rockchip,serial-id = <0x02>;
		rockchip,wake-irq = <0x00>;
		rockchip,irq-mode-enable = <0x00>;
		rockchip,baudrate = <0x1c200>;
		pinctrl-names = "default";
		pinctrl-0 = <&uart2_xfer>;
		status = "okay";
	};

	psci {
		compatible = "arm,psci-1.0";
		method = "smc";
	};

	rockchip-key {
		compatible = "rockchip,key";
		status = "okay";
		io-channels = <0xae 0x01>;

		vol-up-key {
			linux,code = <0x73>;
			label = "volume up";
			rockchip,adc_value = <0x1fe>;
		};

		vol-down-key {
			linux,code = <0x72>;
			label = "volume down";
			rockchip,adc_value = <0x2a8>;
		};

		power-key {
			gpios = <0x3d 0x05 0x01>;
			linux,code = <0x74>;
			pinctrl-names = "default";
			pinctrl-0 = <0xaf>;
			label = "power";
			gpio-key,wakeup;
		};

		home-key {
			linux,code = <0x66>;
			label = "home";
			rockchip,adc_value = <0x361>;
		};

		light-up-key {
			linux,code = <0x1c>;
			label = "light up";
			rockchip,adc_value = <0xaa>;
		};

		light-down-key {
			linux,code = <0xd9>;
			label = "light down";
			rockchip,adc_value = <0x01>;
		};
	};

	dwc-control-usb@ff770284 {
		compatible = "rockchip,rk3288-dwc-control-usb";
		status = "okay";
		reg = <0x00 0xff770284 0x00 0x04 0x00 0xff770288 0x00 0x04 0x00 0xff7702cc 0x00 0x04 0x00 0xff7702d4 0x00 0x04 0x00 0xff770320 0x00 0x14 0x00 0xff770334 0x00 0x14 0x00 0xff770348 0x00 0x10 0x00 0xff770358 0x00 0x08 0x00 0xff770360 0x00 0x08>;
		reg-names = "GRF_SOC_STATUS1", "GRF_SOC_STATUS2", "GRF_SOC_STATUS19", "GRF_SOC_STATUS21", "GRF_UOC0_BASE", "GRF_UOC1_BASE", "GRF_UOC2_BASE", "GRF_UOC3_BASE", "GRF_UOC4_BASE";
		interrupts = <0x00 0x5d 0x04 0x00 0x5e 0x04 0x00 0x5f 0x04 0x00 0x60 0x04 0x00 0x61 0x04>;
		interrupt-names = "otg_id", "otg_bvalid", "otg_linestate", "host0_linestate", "host1_linestate";
		clocks = <0x07 0x1df>;
		clock-names = "hclk_usb_peri";
		otg_drv_gpio = <0x3d 0x0c 0x00>;
		rockchip,remote_wakeup;
		rockchip,usb_irq_wakeup;

		usb_bc {
			compatible = "synopsys,phy";
			rk_usb,bvalid = <0x288 0x0e 0x01>;
			rk_usb,iddig = <0x288 0x11 0x01>;
			rk_usb,dcdenb = <0x328 0x0e 0x01>;
			rk_usb,vdatsrcenb = <0x328 0x07 0x01>;
			rk_usb,vdatdetenb = <0x328 0x06 0x01>;
			rk_usb,chrgsel = <0x328 0x05 0x01>;
			rk_usb,chgdet = <0x2cc 0x17 0x01>;
			rk_usb,fsvminus = <0x2cc 0x19 0x01>;
			rk_usb,fsvplus = <0x2cc 0x18 0x01>;
		};
	};

	nandc@ff400000 {
		compatible = "rockchip,rk-nandc";
		reg = <0x00 0xff400000 0x00 0x4000>;
		interrupts = <0x00 0x26 0x04>;
		nandc_id = <0x00>;
		clocks = <0x07 0x4b 0x07 0x1c5>;
		clock-names = "clk_nandc", "hclk_nandc";
		status = "okay";
	};

	hdmi-analog-sound {
		status = "disabled";
		compatible = "rockchip,rk3288-hdmi-analog", "rockchip,rk3368-hdmi-analog";
		rockchip,model = "rockchip,rt5640-codec";
		rockchip,cpu = <0x9f>;
		rockchip,codec = <0xb0 0xa1>;
		rockchip,widgets = "Microphone", "Microphone Jack", "Headphone", "Headphone Jack";
		rockchip,routing = "MIC1", "Microphone Jack", "MIC2", "Microphone Jack", "Microphone Jack", "micbias1", "Headphone Jack", "HPOL", "Headphone Jack", "HPOR";
	};

	backlight {
		compatible = "pwm-backlight";
		brightness-levels = <0xff 0xfe 0xfd 0xfc 0xfb 0xfa 0xf9 0xf8 0xf7 0xf6 0xf5 0xf4 0xf3 0xf2 0xf1 0xf0 0xef 0xee 0xed 0xec 0xeb 0xea 0xe9 0xe8 0xe7 0xe6 0xe5 0xe4 0xe3 0xe2 0xe1 0xe0 0xdf 0xde 0xdd 0xdc 0xdb 0xda 0xd9 0xd8 0xd7 0xd6 0xd5 0xd4 0xd3 0xd2 0xd1 0xd0 0xcf 0xce 0xcd 0xcc 0xcb 0xca 0xc9 0xc8 0xc7 0xc6 0xc5 0xc4 0xc3 0xc2 0xc1 0xc0 0xbf 0xbe 0xbd 0xbc 0xbb 0xba 0xb9 0xb8 0xb7 0xb6 0xb5 0xb4 0xb3 0xb2 0xb1 0xb0 0xaf 0xae 0xad 0xac 0xab 0xaa 0xa9 0xa8 0xa7 0xa6 0xa5 0xa4 0xa3 0xa2 0xa1 0xa0 0x9f 0x9e 0x9d 0x9c 0x9b 0x9a 0x99 0x98 0x97 0x96 0x95 0x94 0x93 0x92 0x91 0x90 0x8f 0x8e 0x8d 0x8c 0x8b 0x8a 0x89 0x88 0x87 0x86 0x85 0x84 0x83 0x82 0x81 0x80 0x7f 0x7e 0x7d 0x7c 0x7b 0x7a 0x79 0x78 0x77 0x76 0x75 0x74 0x73 0x72 0x71 0x70 0x6f 0x6e 0x6d 0x6c 0x6b 0x6a 0x69 0x68 0x67 0x66 0x65 0x64 0x63 0x62 0x61 0x60 0x5f 0x5e 0x5d 0x5c 0x5b 0x5a 0x59 0x58 0x57 0x56 0x55 0x54 0x53 0x52 0x51 0x50 0x4f 0x4e 0x4d 0x4c 0x4b 0x4a 0x49 0x48 0x47 0x46 0x45 0x44 0x43 0x42 0x41 0x40 0x3f 0x3e 0x3d 0x3c 0x3b 0x3a 0x39 0x38 0x37 0x36 0x35 0x34 0x33 0x32 0x31 0x30 0x2f 0x2e 0x2d 0x2c 0x2b 0x2a 0x29 0x28 0x27 0x26 0x25 0x24 0x23 0x22 0x21 0x20 0x1f 0x1e 0x1d 0x1c 0x1b 0x1a 0x19 0x18 0x17 0x16 0x15 0x14 0x13 0x12 0x11 0x10 0x0f 0x0e 0x0d 0x0c 0x0b 0x0a 0x09 0x08 0x07 0x06 0x05 0x04 0x03 0x02 0x01 0x00>;
		default-brightness-level = <0xff>;
		enable-gpios = <0x3f 0x09 0x00>;
		pinctrl-names = "default";
		pinctrl-0 = <0xb1>;
		pwms = <0xb2 0x00 0x2710 0x00>;
		phandle = <0x85>;
	};

	sdio-pwrseq {
		compatible = "mmc-pwrseq-simple";
		clocks = <0xb3>;
		clock-names = "ext_clock";
		pinctrl-names = "default";
		pinctrl-0 = <0xb4>;
		reset-gpios = <0x4c 0x1c 0x01>;
		phandle = <0x1c>;
	};

	rk_headset {
		compatible = "rockchip_headset";
		headset_gpio = <0x3f 0x07 0x00>;
		io-channels = <0xae 0x02>;
	};

	vcc-lcd {
		compatible = "regulator-fixed";
		regulator-boot-on;
		enable-active-high;
		gpio = <0x3f 0x03 0x00>;
		pinctrl-names = "default";
		pinctrl-0 = <0xb5>;
		regulator-name = "vcc_lcd";
		vin-supply = <0x35>;
		phandle = <0x86>;
	};

	vcc-wl {
		compatible = "regulator-fixed";
		enable-active-low;
		regulator-boot-on;
		pinctrl-names = "default";
		pinctrl-0 = <0xb6>;
		regulator-name = "vcc_wl";
		vin-supply = <0x68>;
	};

	xin32k {
		compatible = "fixed-clock";
		clock-frequency = <0x8000>;
		clock-output-names = "xin32k";
		#clock-cells = <0x00>;
	};
};
